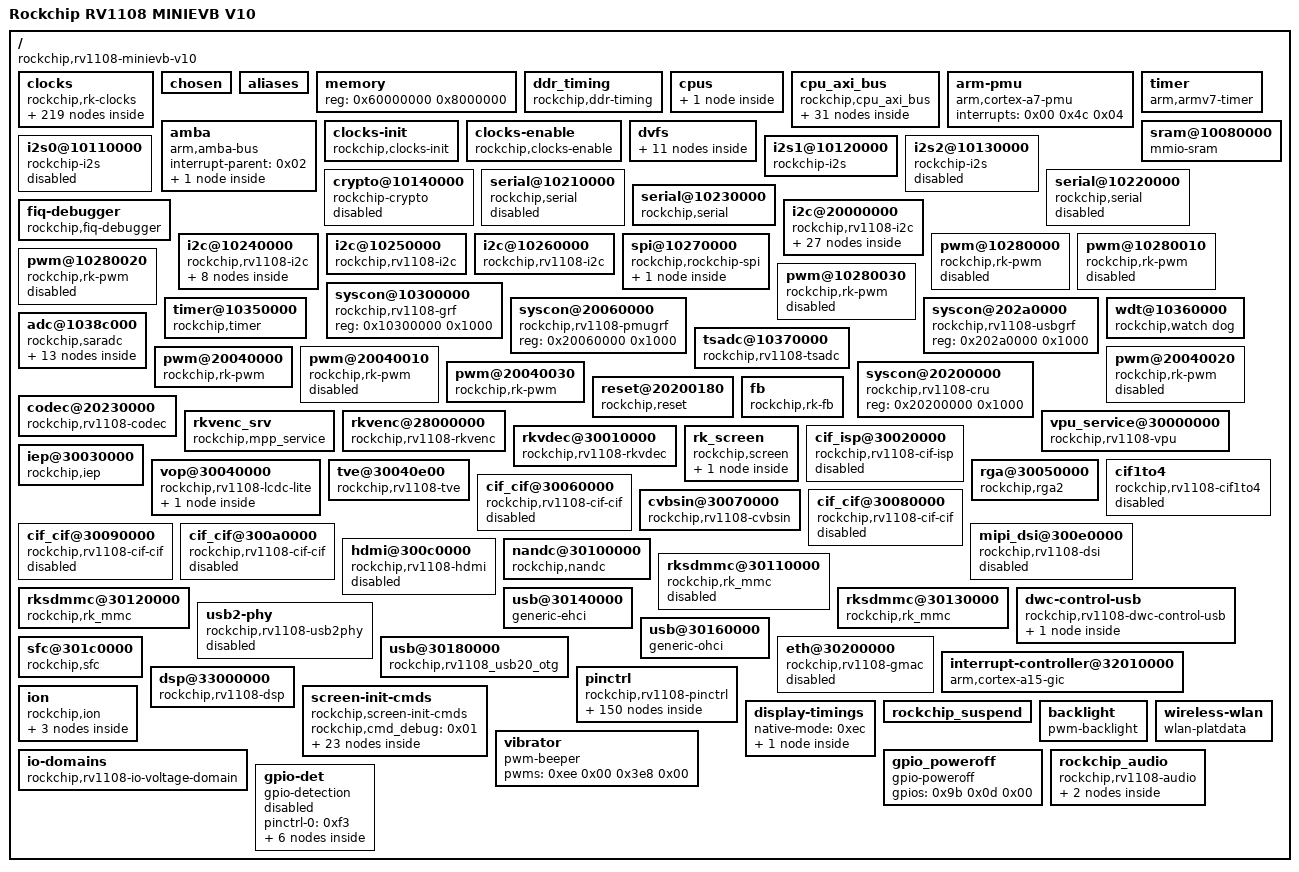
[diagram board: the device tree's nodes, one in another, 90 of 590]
/dts-v1/;

/ {
	#address-cells = <0x01>;
	#size-cells = <0x01>;
	compatible = "rockchip,rv1108-minievb-v10\0rockchip,rv1108";
	rockchip,sram = <0x01>;
	interrupt-parent = <0x02>;
	model = "Rockchip RV1108 MINIEVB V10";

	clocks {
		compatible = "rockchip,rk-clocks";
		#address-cells = <0x01>;
		#size-cells = <0x01>;
		ranges = <0x00 0x20200000 0x1000>;

		fixed_rate_cons {
			compatible = "rockchip,rk-fixed-rate-cons";

			xin24m {
				compatible = "rockchip,rk-fixed-clock";
				clock-output-names = "xin24m";
				clock-frequency = <0x16e3600>;
				#clock-cells = <0x00>;
				linux,phandle = <0x03>;
				phandle = <0x03>;
			};

			xin12m {
				compatible = "rockchip,rk-fixed-clock";
				clocks = <0x03>;
				clock-output-names = "xin12m";
				clock-frequency = <0xb71b00>;
				#clock-cells = <0x00>;
				linux,phandle = <0x12>;
				phandle = <0x12>;
			};

			hdmiphy_pll {
				compatible = "rockchip,rk-fixed-clock";
				clock-output-names = "hdmiphy_pll";
				clock-frequency = <0x2367b880>;
				#clock-cells = <0x00>;
				linux,phandle = <0x56>;
				phandle = <0x56>;
			};

			usbphy_480m {
				compatible = "rockchip,rk-fixed-clock";
				clock-output-names = "usbphy_480m";
				clock-frequency = <0x1c9c3800>;
				#clock-cells = <0x00>;
				linux,phandle = <0x57>;
				phandle = <0x57>;
			};

			pclkin_vip_ninv {
				compatible = "rockchip,rk-fixed-clock";
				clock-output-names = "pclkin_vip_ninv";
				clock-frequency = <0x8f0d180>;
				#clock-cells = <0x00>;
				linux,phandle = <0x3f>;
				phandle = <0x3f>;
			};

			pclkin_vip_inv {
				compatible = "rockchip,rk-fixed-clock";
				clock-output-names = "pclkin_vip_inv";
				clock-frequency = <0x8f0d180>;
				#clock-cells = <0x00>;
				linux,phandle = <0x40>;
				phandle = <0x40>;
			};

			i2s_clkin {
				compatible = "rockchip,rk-fixed-clock";
				clock-output-names = "i2s_clkin";
				clock-frequency = <0x00>;
				#clock-cells = <0x00>;
				linux,phandle = <0x11>;
				phandle = <0x11>;
			};

			gmac_clkin {
				compatible = "rockchip,rk-fixed-clock";
				clock-output-names = "gmac_clkin";
				clock-frequency = <0x2faf080>;
				#clock-cells = <0x00>;
				linux,phandle = <0x2f>;
				phandle = <0x2f>;
			};

			pclkin_cvbs2cif {
				compatible = "rockchip,rk-fixed-clock";
				clock-output-names = "pclkin_cvbs2cif";
				clock-frequency = <0x19bfcc0>;
				#clock-cells = <0x00>;
				linux,phandle = <0x3b>;
				phandle = <0x3b>;
			};

			pclk_cif0_out {
				compatible = "rockchip,rk-fixed-clock";
				clock-output-names = "pclk_cif0_out";
				clock-frequency = <0x8f0d180>;
				#clock-cells = <0x00>;
				linux,phandle = <0x3a>;
				phandle = <0x3a>;
			};

			pclk_cif1_out {
				compatible = "rockchip,rk-fixed-clock";
				clock-output-names = "pclk_cif1_out";
				clock-frequency = <0x8f0d180>;
				#clock-cells = <0x00>;
				linux,phandle = <0x3c>;
				phandle = <0x3c>;
			};

			pclk_cif2_out {
				compatible = "rockchip,rk-fixed-clock";
				clock-output-names = "pclk_cif2_out";
				clock-frequency = <0x8f0d180>;
				#clock-cells = <0x00>;
				linux,phandle = <0x3d>;
				phandle = <0x3d>;
			};

			pclk_cif3_out {
				compatible = "rockchip,rk-fixed-clock";
				clock-output-names = "pclk_cif3_out";
				clock-frequency = <0x8f0d180>;
				#clock-cells = <0x00>;
				linux,phandle = <0x3e>;
				phandle = <0x3e>;
			};

			io_cvbs_clkin {
				compatible = "rockchip,rk-fixed-clock";
				clock-output-names = "io_cvbs_clkin";
				clock-frequency = <0x337f980>;
				#clock-cells = <0x00>;
				linux,phandle = <0x47>;
				phandle = <0x47>;
			};

			clk_jtag_io {
				compatible = "rockchip,rk-fixed-clock";
				clock-output-names = "clk_jtag_io";
				clock-frequency = <0x00>;
				#clock-cells = <0x00>;
				linux,phandle = <0x58>;
				phandle = <0x58>;
			};

			dummy {
				compatible = "rockchip,rk-fixed-clock";
				clock-output-names = "dummy";
				clock-frequency = <0x00>;
				#clock-cells = <0x00>;
				linux,phandle = <0x0a>;
				phandle = <0x0a>;
			};
		};

		fixed_factor_cons {
			compatible = "rockchip,rk-fixed-factor-cons";

			hclk_rkvenc_pre {
				compatible = "rockchip,rk-fixed-factor-clock";
				clocks = <0x04>;
				clock-output-names = "hclk_rkvenc_pre";
				clock-div = <0x04>;
				clock-mult = <0x01>;
				#clock-cells = <0x00>;
				linux,phandle = <0x76>;
				phandle = <0x76>;
			};

			hclk_rkvdec_pre {
				compatible = "rockchip,rk-fixed-factor-clock";
				clocks = <0x05>;
				clock-output-names = "hclk_rkvdec_pre";
				clock-div = <0x04>;
				clock-mult = <0x01>;
				#clock-cells = <0x00>;
				linux,phandle = <0x75>;
				phandle = <0x75>;
			};
		};

		clock_regs {
			compatible = "rockchip,rk-clock-regs";
			#address-cells = <0x01>;
			#size-cells = <0x01>;
			reg = <0x00 0x1000>;
			ranges;

			pll_cons {
				compatible = "rockchip,rk-pll-cons";
				#address-cells = <0x01>;
				#size-cells = <0x01>;
				ranges;

				pll-clk@0000 {
					compatible = "rockchip,rk3188-pll-clk";
					reg = <0x00 0x18>;
					mode-reg = <0x0c 0x08>;
					status-reg = <0x08 0x1f>;
					clocks = <0x03>;
					clock-output-names = "clk_apll";
					rockchip,pll-type = <0x40>;
					#clock-cells = <0x00>;
					linux,phandle = <0x07>;
					phandle = <0x07>;
				};

				pll-clk@0020 {
					compatible = "rockchip,rk3188-pll-clk";
					reg = <0x20 0x18>;
					mode-reg = <0x2c 0x08>;
					status-reg = <0x28 0x1f>;
					clocks = <0x03>;
					clock-output-names = "clk_dpll";
					rockchip,pll-type = <0x100>;
					#clock-cells = <0x00>;
					linux,phandle = <0x09>;
					phandle = <0x09>;
				};

				pll-clk@0040 {
					compatible = "rockchip,rk3188-pll-clk";
					reg = <0x40 0x10>;
					mode-reg = <0x4c 0x08>;
					status-reg = <0x48 0x1f>;
					clocks = <0x03>;
					clock-output-names = "clk_gpll";
					rockchip,pll-type = <0x100>;
					#clock-cells = <0x00>;
					#clock-init-cells = <0x01>;
					linux,phandle = <0x08>;
					phandle = <0x08>;
				};
			};

			clk_sel_cons {
				compatible = "rockchip,rk-sel-cons";
				#address-cells = <0x01>;
				#size-cells = <0x01>;
				ranges;

				sel-con@0060 {
					compatible = "rockchip,rk3188-selcon";
					reg = <0x60 0x04>;
					#address-cells = <0x01>;
					#size-cells = <0x01>;

					clk_core_div {
						compatible = "rockchip,rk3188-div-con";
						rockchip,bits = <0x00 0x05>;
						clocks = <0x06>;
						clock-output-names = "clk_core";
						rockchip,div-type = <0x00>;
						#clock-cells = <0x00>;
						rockchip,clkops-idx = <0x0b>;
						rockchip,flags = <0xc0>;
					};

					clk_core_mux {
						compatible = "rockchip,rk3188-mux-con";
						rockchip,bits = <0x08 0x02>;
						clocks = <0x07 0x08 0x09 0x0a>;
						clock-output-names = "clk_core";
						#clock-cells = <0x00>;
						#clock-init-cells = <0x01>;
						linux,phandle = <0x06>;
						phandle = <0x06>;
					};
				};

				sel-con@0064 {
					compatible = "rockchip,rk3188-selcon";
					reg = <0x64 0x04>;
					#address-cells = <0x01>;
					#size-cells = <0x01>;

					aclk_core_div {
						compatible = "rockchip,rk3188-div-con";
						rockchip,bits = <0x00 0x03>;
						clocks = <0x06>;
						clock-output-names = "aclk_core";
						rockchip,div-type = <0x00>;
						#clock-cells = <0x00>;
						rockchip,clkops-idx = <0x0c>;
						linux,phandle = <0x6d>;
						phandle = <0x6d>;
					};

					pclk_dbg_div {
						compatible = "rockchip,rk3188-div-con";
						rockchip,bits = <0x04 0x04>;
						clocks = <0x06>;
						clock-output-names = "pclk_dbg";
						rockchip,div-type = <0x00>;
						#clock-cells = <0x00>;
						rockchip,clkops-idx = <0x0c>;
						linux,phandle = <0x6e>;
						phandle = <0x6e>;
					};
				};

				sel-con@0068 {
					compatible = "rockchip,rk3188-selcon";
					reg = <0x68 0x04>;
					#address-cells = <0x01>;
					#size-cells = <0x01>;

					aclk_bus_pre_div {
						compatible = "rockchip,rk3188-div-con";
						rockchip,bits = <0x00 0x05>;
						clocks = <0x0b>;
						clock-output-names = "aclk_bus_pre";
						rockchip,div-type = <0x00>;
						#clock-cells = <0x00>;
						#clock-init-cells = <0x01>;
						rockchip,clkops-idx = <0x01>;
						rockchip,flags = <0x100>;
						linux,phandle = <0x0c>;
						phandle = <0x0c>;
					};

					aclk_bus_pre_mux {
						compatible = "rockchip,rk3188-mux-con";
						rockchip,bits = <0x08 0x02>;
						clocks = <0x08 0x0a 0x0a 0x0a>;
						clock-output-names = "aclk_bus_pre";
						#clock-cells = <0x00>;
						#clock-init-cells = <0x01>;
						linux,phandle = <0x0b>;
						phandle = <0x0b>;
					};
				};

				sel-con@006c {
					compatible = "rockchip,rk3188-selcon";
					reg = <0x6c 0x04>;
					#address-cells = <0x01>;
					#size-cells = <0x01>;

					hclk_bus_pre_div {
						compatible = "rockchip,rk3188-div-con";
						rockchip,bits = <0x00 0x05>;
						clocks = <0x0c>;
						clock-output-names = "hclk_bus_pre";
						rockchip,div-type = <0x00>;
						#clock-cells = <0x00>;
						#clock-init-cells = <0x01>;
						linux,phandle = <0x59>;
						phandle = <0x59>;
					};

					pclk_bus_pre_div {
						compatible = "rockchip,rk3188-div-con";
						rockchip,bits = <0x08 0x05>;
						clocks = <0x0c>;
						clock-output-names = "pclk_bus_pre";
						rockchip,div-type = <0x00>;
						#clock-cells = <0x00>;
						#clock-init-cells = <0x01>;
						linux,phandle = <0x5a>;
						phandle = <0x5a>;
					};
				};

				sel-con@0070 {
					compatible = "rockchip,rk3188-selcon";
					reg = <0x70 0x04>;
					#address-cells = <0x01>;
					#size-cells = <0x01>;

					clk_ddr_div {
						compatible = "rockchip,rk3188-div-con";
						rockchip,bits = <0x00 0x03>;
						clocks = <0x0d>;
						clock-output-names = "clk_ddr";
						rockchip,div-type = <0x80>;
						rockchip,div-relations = <0x00 0x01 0x01 0x02 0x03 0x04>;
						#clock-cells = <0x00>;
						rockchip,flags = <0xc0>;
						rockchip,clkops-idx = <0x12>;
						linux,phandle = <0x54>;
						phandle = <0x54>;
					};

					clk_ddr_pll_mux {
						compatible = "rockchip,rk3188-mux-con";
						rockchip,bits = <0x08 0x02>;
						clocks = <0x09 0x0a 0x08 0x0a>;
						clock-output-names = "clk_ddr";
						#clock-cells = <0x00>;
						linux,phandle = <0x0d>;
						phandle = <0x0d>;
					};
				};

				sel-con@0074 {
					compatible = "rockchip,rk3188-selcon";
					reg = <0x74 0x04>;
					#address-cells = <0x01>;
					#size-cells = <0x01>;

					clk_i2s0_pll_div {
						compatible = "rockchip,rk3188-div-con";
						rockchip,bits = <0x00 0x07>;
						clocks = <0x0e>;
						clock-output-names = "clk_i2s0_pll";
						rockchip,div-type = <0x00>;
						#clock-cells = <0x00>;
						rockchip,clkops-idx = <0x01>;
						rockchip,flags = <0x80>;
						linux,phandle = <0x0f>;
						phandle = <0x0f>;
					};

					clk_i2s0_pll_mux {
						compatible = "rockchip,rk3188-mux-con";
						rockchip,bits = <0x08 0x01>;
						clocks = <0x0a 0x08>;
						clock-output-names = "clk_i2s0_pll";
						#clock-cells = <0x00>;
						#clock-init-cells = <0x01>;
						linux,phandle = <0x0e>;
						phandle = <0x0e>;
					};

					clk_i2s0_mux {
						compatible = "rockchip,rk3188-mux-con";
						rockchip,bits = <0x0c 0x02>;
						clocks = <0x0f 0x10 0x11 0x12>;
						clock-output-names = "clk_i2s0";
						#clock-cells = <0x00>;
						rockchip,clkops-idx = <0x0e>;
						rockchip,flags = <0x04>;
						linux,phandle = <0x13>;
						phandle = <0x13>;
					};

					i2s0_clkout_mux {
						compatible = "rockchip,rk3188-mux-con";
						rockchip,bits = <0x0f 0x01>;
						clocks = <0x13 0x12>;
						clock-output-names = "i2s0_clkout";
						#clock-cells = <0x00>;
						#clock-init-cells = <0x01>;
						linux,phandle = <0x5b>;
						phandle = <0x5b>;
					};
				};

				sel-con@0078 {
					compatible = "rockchip,rk3188-selcon";
					reg = <0x78 0x04>;
					#address-cells = <0x01>;
					#size-cells = <0x01>;

					clk_i2s1_pll_div {
						compatible = "rockchip,rk3188-div-con";
						rockchip,bits = <0x00 0x07>;
						clocks = <0x14>;
						clock-output-names = "clk_i2s1_pll";
						rockchip,div-type = <0x00>;
						#clock-cells = <0x00>;
						rockchip,clkops-idx = <0x01>;
						rockchip,flags = <0x80>;
						linux,phandle = <0x15>;
						phandle = <0x15>;
					};

					clk_i2s1_pll_mux {
						compatible = "rockchip,rk3188-mux-con";
						rockchip,bits = <0x08 0x01>;
						clocks = <0x0a 0x08>;
						clock-output-names = "clk_i2s1_pll";
						#clock-cells = <0x00>;
						#clock-init-cells = <0x01>;
						linux,phandle = <0x14>;
						phandle = <0x14>;
					};

					clk_i2s1_mux {
						compatible = "rockchip,rk3188-mux-con";
						rockchip,bits = <0x0c 0x02>;
						clocks = <0x15 0x16 0x0a 0x12>;
						clock-output-names = "clk_i2s1";
						#clock-cells = <0x00>;
						rockchip,clkops-idx = <0x0e>;
						rockchip,flags = <0x04>;
						linux,phandle = <0x5c>;
						phandle = <0x5c>;
					};
				};

				sel-con@007c {
					compatible = "rockchip,rk3188-selcon";
					reg = <0x7c 0x04>;
					#address-cells = <0x01>;
					#size-cells = <0x01>;

					clk_i2s2_pll_div {
						compatible = "rockchip,rk3188-div-con";
						rockchip,bits = <0x00 0x07>;
						clocks = <0x17>;
						clock-output-names = "clk_i2s2_pll";
						rockchip,div-type = <0x00>;
						#clock-cells = <0x00>;
						rockchip,clkops-idx = <0x01>;
						rockchip,flags = <0x80>;
						linux,phandle = <0x18>;
						phandle = <0x18>;
					};

					clk_i2s2_pll_mux {
						compatible = "rockchip,rk3188-mux-con";
						rockchip,bits = <0x08 0x01>;
						clocks = <0x0a 0x08>;
						clock-output-names = "clk_i2s2_pll";
						#clock-cells = <0x00>;
						#clock-init-cells = <0x01>;
						linux,phandle = <0x17>;
						phandle = <0x17>;
					};

					clk_i2s2_mux {
						compatible = "rockchip,rk3188-mux-con";
						rockchip,bits = <0x0c 0x02>;
						clocks = <0x18 0x19 0x0a 0x12>;
						clock-output-names = "clk_i2s2";
						#clock-cells = <0x00>;
						rockchip,clkops-idx = <0x0e>;
						rockchip,flags = <0x04>;
						linux,phandle = <0x5d>;
						phandle = <0x5d>;
					};
				};

				sel-con@0080 {
					compatible = "rockchip,rk3188-selcon";
					reg = <0x80 0x04>;
					#address-cells = <0x01>;
					#size-cells = <0x01>;

					i2s0_frac {
						compatible = "rockchip,rk3188-frac-con";
						clocks = <0x0f>;
						clock-output-names = "i2s0_frac";
						rockchip,bits = <0x00 0x20>;
						rockchip,clkops-idx = <0x05>;
						#clock-cells = <0x00>;
						linux,phandle = <0x10>;
						phandle = <0x10>;
					};
				};

				sel-con@0084 {
					compatible = "rockchip,rk3188-selcon";
					reg = <0x84 0x04>;
					#address-cells = <0x01>;
					#size-cells = <0x01>;

					i2s1_frac {
						compatible = "rockchip,rk3188-frac-con";
						clocks = <0x15>;
						clock-output-names = "i2s1_frac";
						rockchip,bits = <0x00 0x20>;
						rockchip,clkops-idx = <0x05>;
						#clock-cells = <0x00>;
						linux,phandle = <0x16>;
						phandle = <0x16>;
					};
				};

				sel-con@0088 {
					compatible = "rockchip,rk3188-selcon";
					reg = <0x88 0x04>;
					#address-cells = <0x01>;
					#size-cells = <0x01>;

					i2s2_frac {
						compatible = "rockchip,rk3188-frac-con";
						clocks = <0x18>;
						clock-output-names = "i2s2_frac";
						rockchip,bits = <0x00 0x20>;
						rockchip,clkops-idx = <0x05>;
						#clock-cells = <0x00>;
						linux,phandle = <0x19>;
						phandle = <0x19>;
					};
				};

				sel-con@008c {
					compatible = "rockchip,rk3188-selcon";
					reg = <0x8c 0x04>;
					#address-cells = <0x01>;
					#size-cells = <0x01>;

					clk_crypto_div {
						compatible = "rockchip,rk3188-div-con";
						rockchip,bits = <0x00 0x05>;
						clocks = <0x1a>;
						clock-output-names = "clk_crypto";
						rockchip,div-type = <0x00>;
						rockchip,clkops-idx = <0x01>;
						#clock-cells = <0x00>;
						#clock-init-cells = <0x01>;
					};

					clk_crypto_mux {
						compatible = "rockchip,rk3188-mux-con";
						rockchip,bits = <0x07 0x01>;
						clocks = <0x0a 0x08>;
						clock-output-names = "clk_crypto";
						#clock-cells = <0x00>;
						#clock-init-cells = <0x01>;
						linux,phandle = <0x1a>;
						phandle = <0x1a>;
					};

					clk_spi_div {
						compatible = "rockchip,rk3188-div-con";
						rockchip,bits = <0x08 0x07>;
						clocks = <0x1b>;
						clock-output-names = "clk_spi";
						rockchip,div-type = <0x00>;
						#clock-cells = <0x00>;
						rockchip,clkops-idx = <0x01>;
					};

					clk_spi_mux {
						compatible = "rockchip,rk3188-mux-con";
						rockchip,bits = <0x0f 0x01>;
						clocks = <0x0a 0x08>;
						clock-output-names = "clk_spi";
						#clock-cells = <0x00>;
						linux,phandle = <0x1b>;
						phandle = <0x1b>;
					};
				};

				sel-con@0090 {
					compatible = "rockchip,rk3188-selcon";
					reg = <0x90 0x04>;
					#address-cells = <0x01>;
					#size-cells = <0x01>;

					clk_pwm0_div {
						compatible = "rockchip,rk3188-div-con";
						rockchip,bits = <0x00 0x07>;
						clocks = <0x1c>;
						clock-output-names = "clk_pwm0";
						rockchip,div-type = <0x00>;
						#clock-cells = <0x00>;
						rockchip,clkops-idx = <0x01>;
					};

					clk_pwm0_mux {
						compatible = "rockchip,rk3188-mux-con";
						rockchip,bits = <0x07 0x01>;
						clocks = <0x0a 0x08>;
						clock-output-names = "clk_pwm0";
						#clock-cells = <0x00>;
						linux,phandle = <0x1c>;
						phandle = <0x1c>;
					};

					clk_pwm1_div {
						compatible = "rockchip,rk3188-div-con";
						rockchip,bits = <0x08 0x07>;
						clocks = <0x1d>;
						clock-output-names = "clk_pwm1";
						rockchip,div-type = <0x00>;
						#clock-cells = <0x00>;
						rockchip,clkops-idx = <0x01>;
					};

					clk_pwm1_mux {
						compatible = "rockchip,rk3188-mux-con";
						rockchip,bits = <0x0f 0x01>;
						clocks = <0x0a 0x08>;
						clock-output-names = "clk_pwm1";
						#clock-cells = <0x00>;
						linux,phandle = <0x1d>;
						phandle = <0x1d>;
					};
				};

				sel-con@0094 {
					compatible = "rockchip,rk3188-selcon";
					reg = <0x94 0x04>;
					#address-cells = <0x01>;
					#size-cells = <0x01>;

					clk_uart0_pll_div {
						compatible = "rockchip,rk3188-div-con";
						rockchip,bits = <0x00 0x07>;
						clocks = <0x1e>;
						clock-output-names = "clk_uart0_pll";
						rockchip,div-type = <0x00>;
						#clock-cells = <0x00>;
						rockchip,clkops-idx = <0x01>;
						rockchip,flags = <0x80>;
						linux,phandle = <0x1f>;
						phandle = <0x1f>;
					};

					clk_uart0_mux {
						compatible = "rockchip,rk3188-mux-con";
						rockchip,bits = <0x08 0x02>;
						clocks = <0x1f 0x20 0x03>;
						clock-output-names = "clk_uart0";
						#clock-cells = <0x00>;
						rockchip,clkops-idx = <0x0e>;
						rockchip,flags = <0x04>;
						linux,phandle = <0x96>;
						phandle = <0x96>;
					};

					clk_uart0_pll_mux {
						compatible = "rockchip,rk3188-mux-con";
						rockchip,bits = <0x0c 0x02>;
						clocks = <0x0a 0x08 0x21>;
						clock-output-names = "clk_uart0_pll";
						#clock-cells = <0x00>;
						#clock-init-cells = <0x01>;
						linux,phandle = <0x1e>;
						phandle = <0x1e>;
					};
				};

				sel-con@0098 {
					compatible = "rockchip,rk3188-selcon";
					reg = <0x98 0x04>;
					#address-cells = <0x01>;
					#size-cells = <0x01>;

					clk_uart1_pll_div {
						compatible = "rockchip,rk3188-div-con";
						rockchip,bits = <0x00 0x07>;
						clocks = <0x22>;
						clock-output-names = "clk_uart1_pll";
						rockchip,div-type = <0x00>;
						#clock-cells = <0x00>;
						rockchip,clkops-idx = <0x01>;
						rockchip,flags = <0x80>;
						linux,phandle = <0x23>;
						phandle = <0x23>;
					};

					clk_uart1_mux {
						compatible = "rockchip,rk3188-mux-con";
						rockchip,bits = <0x08 0x02>;
						clocks = <0x23 0x24 0x03>;
						clock-output-names = "clk_uart1";
						#clock-cells = <0x00>;
						rockchip,clkops-idx = <0x0e>;
						rockchip,flags = <0x04>;
						linux,phandle = <0x92>;
						phandle = <0x92>;
					};

					clk_uart1_pll_mux {
						compatible = "rockchip,rk3188-mux-con";
						rockchip,bits = <0x0c 0x02>;
						clocks = <0x0a 0x08 0x21>;
						clock-output-names = "clk_uart1_pll";
						#clock-cells = <0x00>;
						#clock-init-cells = <0x01>;
						linux,phandle = <0x22>;
						phandle = <0x22>;
					};
				};

				sel-con@009c {
					compatible = "rockchip,rk3188-selcon";
					reg = <0x9c 0x04>;
					#address-cells = <0x01>;
					#size-cells = <0x01>;

					clk_uart2_pll_div {
						compatible = "rockchip,rk3188-div-con";
						rockchip,bits = <0x00 0x07>;
						clocks = <0x25>;
						clock-output-names = "clk_uart2_pll";
						rockchip,div-type = <0x00>;
						#clock-cells = <0x00>;
						rockchip,clkops-idx = <0x01>;
						rockchip,flags = <0x80>;
						linux,phandle = <0x27>;
						phandle = <0x27>;
					};

					clk_uart2_mux {
						compatible = "rockchip,rk3188-mux-con";
						rockchip,bits = <0x08 0x02>;
						clocks = <0x25 0x26 0x03>;
						clock-output-names = "clk_uart2";
						#clock-cells = <0x00>;
						rockchip,clkops-idx = <0x0e>;
						rockchip,flags = <0x04>;
						linux,phandle = <0x90>;
						phandle = <0x90>;
					};

					clk_uart2_pll_mux {
						compatible = "rockchip,rk3188-mux-con";
						rockchip,bits = <0x0c 0x02>;
						clocks = <0x0a 0x08 0x21>;
						clock-output-names = "clk_uart2_pll";
						#clock-cells = <0x00>;
						#clock-init-cells = <0x01>;
						linux,phandle = <0x25>;
						phandle = <0x25>;
					};
				};

				sel-con@00a0 {
					compatible = "rockchip,rk3188-selcon";
					reg = <0xa0 0x04>;
					#address-cells = <0x01>;
					#size-cells = <0x01>;

					uart0_frac {
						compatible = "rockchip,rk3188-frac-con";
						clocks = <0x1f>;
						clock-output-names = "uart0_frac";
						rockchip,bits = <0x00 0x20>;
						rockchip,clkops-idx = <0x05>;
						#clock-cells = <0x00>;
						linux,phandle = <0x20>;
						phandle = <0x20>;
					};
				};

				sel-con@00a4 {
					compatible = "rockchip,rk3188-selcon";
					reg = <0xa4 0x04>;
					#address-cells = <0x01>;
					#size-cells = <0x01>;

					uart0_frac {
						compatible = "rockchip,rk3188-frac-con";
						clocks = <0x23>;
						clock-output-names = "uart1_frac";
						rockchip,bits = <0x00 0x20>;
						rockchip,clkops-idx = <0x05>;
						#clock-cells = <0x00>;
						linux,phandle = <0x24>;
						phandle = <0x24>;
					};
				};

				sel-con@00a8 {
					compatible = "rockchip,rk3188-selcon";
					reg = <0xa8 0x04>;
					#address-cells = <0x01>;
					#size-cells = <0x01>;

					uart1_frac {
						compatible = "rockchip,rk3188-frac-con";
						clocks = <0x27>;
						clock-output-names = "uart2_frac";
						rockchip,bits = <0x00 0x20>;
						rockchip,clkops-idx = <0x05>;
						#clock-cells = <0x00>;
						linux,phandle = <0x26>;
						phandle = <0x26>;
					};
				};

				sel-con@00ac {
					compatible = "rockchip,rk3188-selcon";
					reg = <0xac 0x04>;
					#address-cells = <0x01>;
					#size-cells = <0x01>;

					clk_i2c0_div {
						compatible = "rockchip,rk3188-div-con";
						rockchip,bits = <0x00 0x07>;
						clocks = <0x28>;
						clock-output-names = "clk_i2c0";
						rockchip,div-type = <0x00>;
						#clock-cells = <0x00>;
						rockchip,clkops-idx = <0x01>;
					};

					clk_i2c0_mux {
						compatible = "rockchip,rk3188-mux-con";
						rockchip,bits = <0x07 0x01>;
						clocks = <0x0a 0x08>;
						clock-output-names = "clk_i2c0";
						#clock-cells = <0x00>;
						linux,phandle = <0x28>;
						phandle = <0x28>;
					};

					clk_i2c1_div {
						compatible = "rockchip,rk3188-div-con";
						rockchip,bits = <0x08 0x07>;
						clocks = <0x29>;
						clock-output-names = "clk_i2c1";
						rockchip,div-type = <0x00>;
						#clock-cells = <0x00>;
						rockchip,clkops-idx = <0x01>;
					};

					clk_i2c1_mux {
						compatible = "rockchip,rk3188-mux-con";
						rockchip,bits = <0x0f 0x01>;
						clocks = <0x0a 0x08>;
						clock-output-names = "clk_i2c1";
						#clock-cells = <0x00>;
						linux,phandle = <0x29>;
						phandle = <0x29>;
					};
				};

				sel-con@00b0 {
					compatible = "rockchip,rk3188-selcon";
					reg = <0xb0 0x04>;
					#address-cells = <0x01>;
					#size-cells = <0x01>;

					clk_i2c2_div {
						compatible = "rockchip,rk3188-div-con";
						rockchip,bits = <0x00 0x07>;
						clocks = <0x2a>;
						clock-output-names = "clk_i2c2";
						rockchip,div-type = <0x00>;
						#clock-cells = <0x00>;
						rockchip,clkops-idx = <0x01>;
					};

					clk_i2c2_mux {
						compatible = "rockchip,rk3188-mux-con";
						rockchip,bits = <0x07 0x01>;
						clocks = <0x0a 0x08>;
						clock-output-names = "clk_i2c2";
						#clock-cells = <0x00>;
						linux,phandle = <0x2a>;
						phandle = <0x2a>;
					};

					clk_i2c3_div {
						compatible = "rockchip,rk3188-div-con";
						rockchip,bits = <0x08 0x07>;
						clocks = <0x2b>;
						clock-output-names = "clk_i2c3";
						rockchip,div-type = <0x00>;
						#clock-cells = <0x00>;
						rockchip,clkops-idx = <0x01>;
					};

					clk_i2c3_mux {
						compatible = "rockchip,rk3188-mux-con";
						rockchip,bits = <0x0f 0x01>;
						clocks = <0x0a 0x08>;
						clock-output-names = "clk_i2c3";
						#clock-cells = <0x00>;
						linux,phandle = <0x2b>;
						phandle = <0x2b>;
					};
				};

				sel-con@00b4 {
					compatible = "rockchip,rk3188-selcon";
					reg = <0xb4 0x04>;
					#address-cells = <0x01>;
					#size-cells = <0x01>;

					clk_tsadc_div {
						compatible = "rockchip,rk3188-div-con";
						rockchip,bits = <0x00 0x0a>;
						clocks = <0x03>;
						clock-output-names = "clk_tsadc";
						rockchip,div-type = <0x00>;
						#clock-cells = <0x00>;
						rockchip,clkops-idx = <0x01>;
						linux,phandle = <0x5e>;
						phandle = <0x5e>;
					};
				};

				sel-con@00b8 {
					compatible = "rockchip,rk3188-selcon";
					reg = <0xb8 0x04>;
					#address-cells = <0x01>;
					#size-cells = <0x01>;

					clk_saradc_div {
						compatible = "rockchip,rk3188-div-con";
						rockchip,bits = <0x00 0x0a>;
						clocks = <0x03>;
						clock-output-names = "clk_saradc";
						rockchip,div-type = <0x00>;
						#clock-cells = <0x00>;
						rockchip,clkops-idx = <0x01>;
						linux,phandle = <0x5f>;
						phandle = <0x5f>;
					};
				};

				sel-con@00bc {
					compatible = "rockchip,rk3188-selcon";
					reg = <0xbc 0x04>;
					#address-cells = <0x01>;
					#size-cells = <0x01>;

					aclk_peri_div {
						compatible = "rockchip,rk3188-div-con";
						rockchip,bits = <0x00 0x05>;
						clocks = <0x2c>;
						clock-output-names = "aclk_peri";
						rockchip,div-type = <0x00>;
						#clock-cells = <0x00>;
						rockchip,clkops-idx = <0x01>;
					};

					hclk_peri_div {
						compatible = "rockchip,rk3188-div-con";
						rockchip,bits = <0x05 0x05>;
						clocks = <0x08>;
						clock-output-names = "hclk_peri";
						rockchip,div-type = <0x00>;
						#clock-cells = <0x00>;
						rockchip,clkops-idx = <0x01>;
						#clock-init-cells = <0x01>;
						linux,phandle = <0x70>;
						phandle = <0x70>;
					};

					pclk_peri_div {
						compatible = "rockchip,rk3188-div-con";
						rockchip,bits = <0x0a 0x05>;
						clocks = <0x08>;
						clock-output-names = "pclk_peri";
						rockchip,div-type = <0x00>;
						#clock-cells = <0x00>;
						rockchip,clkops-idx = <0x01>;
						#clock-init-cells = <0x01>;
						linux,phandle = <0x71>;
						phandle = <0x71>;
					};

					aclk_peri_mux {
						compatible = "rockchip,rk3188-mux-con";
						rockchip,bits = <0x0f 0x01>;
						clocks = <0x08 0x0a>;
						clock-output-names = "aclk_peri";
						#clock-cells = <0x00>;
						#clock-init-cells = <0x01>;
						linux,phandle = <0x2c>;
						phandle = <0x2c>;
					};
				};

				sel-con@00c0 {
					compatible = "rockchip,rk3188-selcon";
					reg = <0xc0 0x04>;
					#address-cells = <0x01>;
					#size-cells = <0x01>;

					clk_mac_pll_div {
						compatible = "rockchip,rk3188-div-con";
						rockchip,bits = <0x00 0x05>;
						clocks = <0x2d>;
						clock-output-names = "clk_mac_pll";
						rockchip,div-type = <0x00>;
						#clock-cells = <0x00>;
						rockchip,clkops-idx = <0x01>;
						rockchip,flags = <0x100>;
						linux,phandle = <0x2e>;
						phandle = <0x2e>;
					};

					clk_mac_mux {
						compatible = "rockchip,rk3188-mux-con";
						rockchip,bits = <0x08 0x01>;
						clocks = <0x2e 0x2f>;
						clock-output-names = "clk_mac";
						#clock-cells = <0x00>;
						rockchip,flags = <0x04>;
						#clock-init-cells = <0x01>;
						linux,phandle = <0x60>;
						phandle = <0x60>;
					};

					clk_mac_pll_mux {
						compatible = "rockchip,rk3188-mux-con";
						rockchip,bits = <0x0c 0x01>;
						clocks = <0x07 0x08>;
						clock-output-names = "clk_mac_pll";
						#clock-cells = <0x00>;
						rockchip,flags = <0xc0>;
						#clock-init-cells = <0x01>;
						linux,phandle = <0x2d>;
						phandle = <0x2d>;
					};
				};

				sel-con@00c4 {
					compatible = "rockchip,rk3188-selcon";
					reg = <0xc4 0x04>;
					#address-cells = <0x01>;
					#size-cells = <0x01>;

					clk_sdmmc_div {
						compatible = "rockchip,rk3188-div-con";
						rockchip,bits = <0x00 0x08>;
						clocks = <0x30>;
						clock-output-names = "clk_sdmmc";
						rockchip,div-type = <0x00>;
						#clock-cells = <0x00>;
						rockchip,clkops-idx = <0x01>;
						rockchip,flags = <0x100>;
					};

					clk_sdmmc_mux {
						compatible = "rockchip,rk3188-mux-con";
						rockchip,bits = <0x08 0x02>;
						clocks = <0x0a 0x08 0x03 0x21>;
						clock-output-names = "clk_sdmmc";
						#clock-cells = <0x00>;
						linux,phandle = <0x30>;
						phandle = <0x30>;
					};

					clk_sdio_mux {
						compatible = "rockchip,rk3188-mux-con";
						rockchip,bits = <0x0a 0x02>;
						clocks = <0x0a 0x08 0x03 0x21>;
						clock-output-names = "clk_sdio";
						#clock-cells = <0x00>;
						#clock-init-cells = <0x01>;
						linux,phandle = <0x31>;
						phandle = <0x31>;
					};

					clk_emmc_mux {
						compatible = "rockchip,rk3188-mux-con";
						rockchip,bits = <0x0c 0x02>;
						clocks = <0x0a 0x08 0x03 0x21>;
						clock-output-names = "clk_emmc";
						#clock-cells = <0x00>;
						#clock-init-cells = <0x01>;
						linux,phandle = <0x32>;
						phandle = <0x32>;
					};
				};

				sel-con@00c8 {
					compatible = "rockchip,rk3188-selcon";
					reg = <0xc8 0x04>;
					#address-cells = <0x01>;
					#size-cells = <0x01>;

					clk_sdio_div {
						compatible = "rockchip,rk3188-div-con";
						rockchip,bits = <0x00 0x08>;
						clocks = <0x31>;
						clock-output-names = "clk_sdio";
						rockchip,div-type = <0x00>;
						#clock-cells = <0x00>;
						rockchip,clkops-idx = <0x01>;
						rockchip,flags = <0x100>;
					};

					clk_emmc_div {
						compatible = "rockchip,rk3188-div-con";
						rockchip,bits = <0x08 0x08>;
						clocks = <0x32>;
						clock-output-names = "clk_emmc";
						rockchip,div-type = <0x00>;
						#clock-cells = <0x00>;
						rockchip,clkops-idx = <0x01>;
						rockchip,flags = <0x100>;
					};
				};

				sel-con@00cc {
					compatible = "rockchip,rk3188-selcon";
					reg = <0xcc 0x04>;
					#address-cells = <0x01>;
					#size-cells = <0x01>;

					clk_sfc_div {
						compatible = "rockchip,rk3188-div-con";
						rockchip,bits = <0x00 0x07>;
						clocks = <0x33>;
						clock-output-names = "clk_sfc";
						rockchip,div-type = <0x00>;
						#clock-cells = <0x00>;
						rockchip,clkops-idx = <0x01>;
					};

					clk_sfc_mux {
						compatible = "rockchip,rk3188-mux-con";
						rockchip,bits = <0x07 0x01>;
						clocks = <0x0a 0x08>;
						clock-output-names = "clk_sfc";
						#clock-cells = <0x00>;
						linux,phandle = <0x33>;
						phandle = <0x33>;
					};

					clk_nandc_div {
						compatible = "rockchip,rk3188-div-con";
						rockchip,bits = <0x08 0x05>;
						clocks = <0x34>;
						clock-output-names = "clk_nandc";
						rockchip,div-type = <0x00>;
						#clock-cells = <0x00>;
						rockchip,clkops-idx = <0x01>;
					};

					clk_nandc_mux {
						compatible = "rockchip,rk3188-mux-con";
						rockchip,bits = <0x0e 0x01>;
						clocks = <0x0a 0x08>;
						clock-output-names = "clk_nandc";
						#clock-cells = <0x00>;
						#clock-init-cells = <0x01>;
						linux,phandle = <0x34>;
						phandle = <0x34>;
					};
				};

				sel-con@00d0 {
					compatible = "rockchip,rk3188-selcon";
					reg = <0xd0 0x04>;
					#address-cells = <0x01>;
					#size-cells = <0x01>;

					aclk_vio0_pre_div {
						compatible = "rockchip,rk3188-div-con";
						rockchip,bits = <0x00 0x05>;
						clocks = <0x35>;
						clock-output-names = "aclk_vio0_pre";
						rockchip,div-type = <0x00>;
						#clock-cells = <0x00>;
						rockchip,clkops-idx = <0x01>;
						rockchip,flags = <0x100>;
						#clock-init-cells = <0x01>;
						linux,phandle = <0x37>;
						phandle = <0x37>;
					};

					aclk_vio0_pre_mux {
						compatible = "rockchip,rk3188-mux-con";
						rockchip,bits = <0x06 0x02>;
						clocks = <0x0a 0x08 0x0a 0x21>;
						clock-output-names = "aclk_vio0_pre";
						#clock-cells = <0x00>;
						#clock-init-cells = <0x01>;
						linux,phandle = <0x35>;
						phandle = <0x35>;
					};

					aclk_vio1_pre_div {
						compatible = "rockchip,rk3188-div-con";
						rockchip,bits = <0x08 0x05>;
						clocks = <0x36>;
						clock-output-names = "aclk_vio1_pre";
						rockchip,div-type = <0x00>;
						#clock-cells = <0x00>;
						rockchip,clkops-idx = <0x01>;
						rockchip,flags = <0x100>;
						#clock-init-cells = <0x01>;
					};

					aclk_vio1_pre_mux {
						compatible = "rockchip,rk3188-mux-con";
						rockchip,bits = <0x0e 0x02>;
						clocks = <0x0a 0x08 0x0a 0x21>;
						clock-output-names = "aclk_vio1_pre";
						#clock-cells = <0x00>;
						#clock-init-cells = <0x01>;
						linux,phandle = <0x36>;
						phandle = <0x36>;
					};
				};

				sel-con@00d4 {
					compatible = "rockchip,rk3188-selcon";
					reg = <0xd4 0x04>;
					#address-cells = <0x01>;
					#size-cells = <0x01>;

					hclk_vio_pre_div {
						compatible = "rockchip,rk3188-div-con";
						rockchip,bits = <0x00 0x05>;
						clocks = <0x37>;
						clock-output-names = "hclk_vio_pre";
						rockchip,div-type = <0x00>;
						#clock-cells = <0x00>;
						rockchip,clkops-idx = <0x01>;
						#clock-init-cells = <0x01>;
						linux,phandle = <0x72>;
						phandle = <0x72>;
					};

					pclk_vio_pre_div {
						compatible = "rockchip,rk3188-div-con";
						rockchip,bits = <0x08 0x05>;
						clocks = <0x37>;
						clock-output-names = "pclk_vio_pre";
						rockchip,div-type = <0x00>;
						#clock-cells = <0x00>;
						rockchip,clkops-idx = <0x01>;
						#clock-init-cells = <0x01>;
						linux,phandle = <0x73>;
						phandle = <0x73>;
					};
				};

				sel-con@00d8 {
					compatible = "rockchip,rk3188-selcon";
					reg = <0xd8 0x04>;
					#address-cells = <0x01>;
					#size-cells = <0x01>;

					clk_isp_div {
						compatible = "rockchip,rk3188-div-con";
						rockchip,bits = <0x08 0x05>;
						clocks = <0x38>;
						clock-output-names = "clk_isp";
						rockchip,div-type = <0x00>;
						#clock-cells = <0x00>;
						rockchip,clkops-idx = <0x01>;
						rockchip,flags = <0x100>;
					};

					clk_isp_mux {
						compatible = "rockchip,rk3188-mux-con";
						rockchip,bits = <0x0e 0x02>;
						clocks = <0x0a 0x08 0x0a 0x21>;
						clock-output-names = "clk_isp";
						#clock-cells = <0x00>;
						#clock-init-cells = <0x01>;
						linux,phandle = <0x38>;
						phandle = <0x38>;
					};
				};

				sel-con@00dc {
					compatible = "rockchip,rk3188-selcon";
					reg = <0xdc 0x04>;
					#address-cells = <0x01>;
					#size-cells = <0x01>;

					vip0_clk_mux {
						compatible = "rockchip,rk3188-mux-con";
						rockchip,bits = <0x00 0x02>;
						clocks = <0x39 0x3a 0x3b 0x3b>;
						clock-output-names = "vip0_clk";
						#clock-cells = <0x00>;
						#clock-init-cells = <0x01>;
						linux,phandle = <0x61>;
						phandle = <0x61>;
					};

					vip1_clk_mux {
						compatible = "rockchip,rk3188-mux-con";
						rockchip,bits = <0x02 0x02>;
						clocks = <0x39 0x3c 0x3b 0x3b>;
						clock-output-names = "vip1_clk";
						#clock-cells = <0x00>;
						#clock-init-cells = <0x01>;
						linux,phandle = <0x62>;
						phandle = <0x62>;
					};

					vip2_clk_mux {
						compatible = "rockchip,rk3188-mux-con";
						rockchip,bits = <0x04 0x02>;
						clocks = <0x39 0x3d 0x3b 0x3b>;
						clock-output-names = "vip2_clk";
						#clock-cells = <0x00>;
						#clock-init-cells = <0x01>;
						linux,phandle = <0x63>;
						phandle = <0x63>;
					};

					vip3_clk_mux {
						compatible = "rockchip,rk3188-mux-con";
						rockchip,bits = <0x06 0x02>;
						clocks = <0x39 0x3e 0x3b 0x3b>;
						clock-output-names = "vip3_clk";
						#clock-cells = <0x00>;
						#clock-init-cells = <0x01>;
						linux,phandle = <0x64>;
						phandle = <0x64>;
					};

					pclkin_vip_mux {
						compatible = "rockchip,rk3188-mux-con";
						rockchip,bits = <0x08 0x01>;
						clocks = <0x3f 0x40>;
						clock-output-names = "pclkin_vip";
						#clock-cells = <0x00>;
						#clock-init-cells = <0x01>;
						linux,phandle = <0x39>;
						phandle = <0x39>;
					};
				};

				sel-con@00e0 {
					compatible = "rockchip,rk3188-selcon";
					reg = <0xe0 0x04>;
					#address-cells = <0x01>;
					#size-cells = <0x01>;

					dclk_vop_div {
						compatible = "rockchip,rk3188-div-con";
						rockchip,bits = <0x00 0x06>;
						clocks = <0x41>;
						clock-output-names = "dclk_vop";
						rockchip,div-type = <0x00>;
						#clock-cells = <0x00>;
						linux,phandle = <0x43>;
						phandle = <0x43>;
					};

					dclk_vop_pll_mux {
						compatible = "rockchip,rk3188-mux-con";
						rockchip,bits = <0x06 0x01>;
						clocks = <0x08 0x0a>;
						clock-output-names = "dclk_vop_pll";
						#clock-cells = <0x00>;
						#clock-init-cells = <0x01>;
						linux,phandle = <0x41>;
						phandle = <0x41>;
					};

					dclk_lcdc_mux {
						compatible = "rockchip,rk3188-mux-con";
						rockchip,bits = <0x07 0x01>;
						clocks = <0x42 0x43>;
						clock-output-names = "dclk_lcdc";
						rockchip,flags = <0x04>;
						#clock-cells = <0x00>;
						#clock-init-cells = <0x01>;
						linux,phandle = <0x55>;
						phandle = <0x55>;
					};

					dclk_hdmiphy_div {
						compatible = "rockchip,rk3188-div-con";
						rockchip,bits = <0x08 0x06>;
						clocks = <0x41>;
						clock-output-names = "dclk_hdmiphy";
						rockchip,div-type = <0x00>;
						#clock-cells = <0x00>;
						linux,phandle = <0xcf>;
						phandle = <0xcf>;
					};

					dclk_lcdc_pll_mux {
						compatible = "rockchip,rk3188-mux-con";
						rockchip,bits = <0x0f 0x01>;
						clocks = <0x44 0x03>;
						clock-output-names = "dclk_lcdc_pll";
						#clock-cells = <0x00>;
						#clock-init-cells = <0x01>;
						linux,phandle = <0x42>;
						phandle = <0x42>;
					};
				};

				sel-con@00e4 {
					compatible = "rockchip,rk3188-selcon";
					reg = <0xe4 0x04>;
					#address-cells = <0x01>;
					#size-cells = <0x01>;

					clk_rga_div {
						compatible = "rockchip,rk3188-div-con";
						rockchip,bits = <0x00 0x05>;
						clocks = <0x45>;
						clock-output-names = "clk_rga";
						rockchip,div-type = <0x00>;
						#clock-cells = <0x00>;
						rockchip,clkops-idx = <0x01>;
						rockchip,flags = <0x100>;
						#clock-init-cells = <0x01>;
					};

					clk_rga_mux {
						compatible = "rockchip,rk3188-mux-con";
						rockchip,bits = <0x06 0x02>;
						clocks = <0x0a 0x08 0x0a 0x21>;
						clock-output-names = "clk_rga";
						#clock-cells = <0x00>;
						#clock-init-cells = <0x01>;
						linux,phandle = <0x45>;
						phandle = <0x45>;
					};

					clk_cvbs_host_div {
						compatible = "rockchip,rk3188-div-con";
						rockchip,bits = <0x08 0x05>;
						clocks = <0x46>;
						clock-output-names = "clk_cvbs_host";
						rockchip,div-type = <0x00>;
						#clock-cells = <0x00>;
						rockchip,clkops-idx = <0x01>;
						rockchip,flags = <0x180>;
					};

					clk_cvbs_host_mux {
						compatible = "rockchip,rk3188-mux-con";
						rockchip,bits = <0x0d 0x02>;
						clocks = <0x0a 0x47 0x0a 0x08>;
						clock-output-names = "clk_cvbs_host";
						#clock-cells = <0x00>;
						#clock-init-cells = <0x01>;
						linux,phandle = <0x46>;
						phandle = <0x46>;
					};
				};

				sel-con@00e8 {
					compatible = "rockchip,rk3188-selcon";
					reg = <0xe8 0x04>;
					#address-cells = <0x01>;
					#size-cells = <0x01>;

					clk_hdmi_cec_div {
						compatible = "rockchip,rk3188-div-con";
						rockchip,bits = <0x00 0x0e>;
						clocks = <0x48>;
						clock-output-names = "clk_hdmi_cec";
						rockchip,div-type = <0x00>;
						#clock-cells = <0x00>;
						rockchip,clkops-idx = <0x01>;
					};

					clk_hdmi_cec_mux {
						compatible = "rockchip,rk3188-mux-con";
						rockchip,bits = <0x0e 0x02>;
						clocks = <0x0a 0x08 0x03 0x0a>;
						clock-output-names = "clk_hdmi_cec";
						#clock-cells = <0x00>;
						#clock-init-cells = <0x01>;
						linux,phandle = <0x48>;
						phandle = <0x48>;
					};
				};

				sel-con@00ec {
					compatible = "rockchip,rk3188-selcon";
					reg = <0xec 0x04>;
					#address-cells = <0x01>;
					#size-cells = <0x01>;

					aclk_rkvdec_pre_div {
						compatible = "rockchip,rk3188-div-con";
						rockchip,bits = <0x00 0x05>;
						clocks = <0x49>;
						clock-output-names = "aclk_rkvdec_pre";
						rockchip,div-type = <0x00>;
						#clock-cells = <0x00>;
						rockchip,clkops-idx = <0x01>;
						rockchip,flags = <0x100>;
					};

					aclk_rkvdec_pre_mux {
						compatible = "rockchip,rk3188-mux-con";
						rockchip,bits = <0x06 0x02>;
						clocks = <0x0a 0x08 0x0a 0x21>;
						clock-output-names = "aclk_rkvdec_pre";
						#clock-cells = <0x00>;
						#clock-init-cells = <0x01>;
						linux,phandle = <0x49>;
						phandle = <0x49>;
					};

					clk_hevc_cabac_div {
						compatible = "rockchip,rk3188-div-con";
						rockchip,bits = <0x08 0x05>;
						clocks = <0x4a>;
						clock-output-names = "clk_hevc_cabac";
						rockchip,div-type = <0x00>;
						#clock-cells = <0x00>;
						rockchip,clkops-idx = <0x01>;
						rockchip,flags = <0x100>;
					};

					clk_hevc_cabac_mux {
						compatible = "rockchip,rk3188-mux-con";
						rockchip,bits = <0x0e 0x02>;
						clocks = <0x0a 0x08 0x0a 0x21>;
						clock-output-names = "clk_hevc_cabac";
						#clock-cells = <0x00>;
						#clock-init-cells = <0x01>;
						linux,phandle = <0x4a>;
						phandle = <0x4a>;
					};
				};

				sel-con@00f0 {
					compatible = "rockchip,rk3188-selcon";
					reg = <0xf0 0x04>;
					#address-cells = <0x01>;
					#size-cells = <0x01>;

					clk_hevc_core_div {
						compatible = "rockchip,rk3188-div-con";
						rockchip,bits = <0x00 0x05>;
						clocks = <0x05>;
						clock-output-names = "clk_hevc_core";
						rockchip,div-type = <0x00>;
						#clock-cells = <0x00>;
						rockchip,clkops-idx = <0x01>;
						rockchip,flags = <0x100>;
						#clock-init-cells = <0x01>;
					};

					clk_hevc_core_mux {
						compatible = "rockchip,rk3188-mux-con";
						rockchip,bits = <0x06 0x02>;
						clocks = <0x0a 0x08 0x0a 0x21>;
						clock-output-names = "clk_hevc_core";
						#clock-cells = <0x00>;
						#clock-init-cells = <0x01>;
						linux,phandle = <0x05>;
						phandle = <0x05>;
					};

					aclk_vpu_pre_div {
						compatible = "rockchip,rk3188-div-con";
						rockchip,bits = <0x08 0x05>;
						clocks = <0x4b>;
						clock-output-names = "aclk_vpu_pre";
						rockchip,div-type = <0x00>;
						#clock-cells = <0x00>;
						rockchip,clkops-idx = <0x01>;
						rockchip,flags = <0x100>;
						#clock-init-cells = <0x01>;
					};

					aclk_vpu_pre_mux {
						compatible = "rockchip,rk3188-mux-con";
						rockchip,bits = <0x0e 0x02>;
						clocks = <0x0a 0x08 0x0a 0x21>;
						clock-output-names = "aclk_vpu_pre";
						#clock-cells = <0x00>;
						#clock-init-cells = <0x01>;
						linux,phandle = <0x4b>;
						phandle = <0x4b>;
					};
				};

				sel-con@00f4 {
					compatible = "rockchip,rk3188-selcon";
					reg = <0xf4 0x04>;
					#address-cells = <0x01>;
					#size-cells = <0x01>;

					aclk_rkvenc_pre_div {
						compatible = "rockchip,rk3188-div-con";
						rockchip,bits = <0x00 0x05>;
						clocks = <0x04>;
						clock-output-names = "aclk_rkvenc_pre";
						rockchip,div-type = <0x00>;
						#clock-cells = <0x00>;
						rockchip,clkops-idx = <0x01>;
						rockchip,flags = <0x100>;
					};

					aclk_rkvenc_pre_mux {
						compatible = "rockchip,rk3188-mux-con";
						rockchip,bits = <0x06 0x02>;
						clocks = <0x0a 0x08 0x0a 0x21>;
						clock-output-names = "aclk_rkvenc_pre";
						#clock-cells = <0x00>;
						#clock-init-cells = <0x01>;
						linux,phandle = <0x04>;
						phandle = <0x04>;
					};

					clk_venc_core_div {
						compatible = "rockchip,rk3188-div-con";
						rockchip,bits = <0x08 0x05>;
						clocks = <0x4c>;
						clock-output-names = "clk_venc_core";
						rockchip,div-type = <0x00>;
						#clock-cells = <0x00>;
						rockchip,clkops-idx = <0x01>;
						rockchip,flags = <0x100>;
					};

					clk_venc_core_mux {
						compatible = "rockchip,rk3188-mux-con";
						rockchip,bits = <0x0e 0x02>;
						clocks = <0x0a 0x08 0x0a 0x21>;
						clock-output-names = "clk_venc_core";
						#clock-cells = <0x00>;
						#clock-init-cells = <0x01>;
						linux,phandle = <0x4c>;
						phandle = <0x4c>;
					};
				};

				sel-con@00f8 {
					compatible = "rockchip,rk3188-selcon";
					reg = <0xf8 0x04>;
					#address-cells = <0x01>;
					#size-cells = <0x01>;

					pclk_pmu_pre_div {
						compatible = "rockchip,rk3188-div-con";
						rockchip,bits = <0x00 0x05>;
						clocks = <0x08>;
						clock-output-names = "pclk_pmu_pre";
						rockchip,div-type = <0x00>;
						#clock-cells = <0x00>;
						linux,phandle = <0x65>;
						phandle = <0x65>;
					};
				};

				sel-con@00fc {
					compatible = "rockchip,rk3188-selcon";
					reg = <0xfc 0x04>;
					#address-cells = <0x01>;
					#size-cells = <0x01>;

					clk_test_div {
						compatible = "rockchip,rk3188-div-con";
						rockchip,bits = <0x08 0x05>;
						clocks = <0x4d>;
						clock-output-names = "clk_test";
						rockchip,div-type = <0x00>;
						#clock-cells = <0x00>;
						rockchip,clkops-idx = <0x01>;
						linux,phandle = <0x6b>;
						phandle = <0x6b>;
					};
				};

				sel-con@0100 {
					compatible = "rockchip,rk3188-selcon";
					reg = <0x100 0x04>;
					#address-cells = <0x01>;
					#size-cells = <0x01>;

					clk_cif_out_div {
						compatible = "rockchip,rk3188-div-con";
						rockchip,bits = <0x00 0x05>;
						clocks = <0x4e>;
						clock-output-names = "clk_cif_out";
						rockchip,div-type = <0x00>;
						#clock-cells = <0x00>;
						rockchip,clkops-idx = <0x01>;
					};

					clk_cif_pll_mux {
						compatible = "rockchip,rk3188-mux-con";
						rockchip,bits = <0x08 0x01>;
						clocks = <0x0a 0x08>;
						clock-output-names = "clk_cif_pll";
						#clock-cells = <0x00>;
						linux,phandle = <0x4f>;
						phandle = <0x4f>;
					};

					clk_cif_out_mux {
						compatible = "rockchip,rk3188-mux-con";
						rockchip,bits = <0x0c 0x01>;
						clocks = <0x4f 0x03>;
						clock-output-names = "clk_cif_out";
						#clock-cells = <0x00>;
						linux,phandle = <0x4e>;
						phandle = <0x4e>;
					};
				};

				sel-con@0104 {
					compatible = "rockchip,rk3188-selcon";
					reg = <0x104 0x04>;
					#address-cells = <0x01>;
					#size-cells = <0x01>;

					clk_mipicsi_out_div {
						compatible = "rockchip,rk3188-div-con";
						rockchip,bits = <0x00 0x05>;
						clocks = <0x03>;
						clock-output-names = "clk_mipicsi_out";
						rockchip,div-type = <0x00>;
						#clock-cells = <0x00>;
						rockchip,clkops-idx = <0x01>;
						linux,phandle = <0x6c>;
						phandle = <0x6c>;
					};

					clk_wifi_div {
						compatible = "rockchip,rk3188-div-con";
						rockchip,bits = <0x08 0x06>;
						clocks = <0x50>;
						clock-output-names = "clk_wifi";
						rockchip,div-type = <0x00>;
						#clock-cells = <0x00>;
						rockchip,clkops-idx = <0x01>;
					};

					clk_wifi_mux {
						compatible = "rockchip,rk3188-mux-con";
						rockchip,bits = <0x0f 0x01>;
						clocks = <0x08 0x03>;
						clock-output-names = "clk_wifi";
						#clock-cells = <0x00>;
						linux,phandle = <0x50>;
						phandle = <0x50>;
					};
				};

				sel-con@0108 {
					compatible = "rockchip,rk3188-selcon";
					reg = <0x108 0x04>;
					#address-cells = <0x01>;
					#size-cells = <0x01>;

					clk_dsp_div {
						compatible = "rockchip,rk3188-div-con";
						rockchip,bits = <0x00 0x05>;
						clocks = <0x51>;
						clock-output-names = "clk_dsp";
						rockchip,div-type = <0x00>;
						#clock-cells = <0x00>;
						rockchip,clkops-idx = <0x01>;
						rockchip,flags = <0x100>;
						linux,phandle = <0x52>;
						phandle = <0x52>;
					};

					clk_dsp_mux {
						compatible = "rockchip,rk3188-mux-con";
						rockchip,bits = <0x08 0x02>;
						clocks = <0x0a 0x08 0x0a 0x21>;
						clock-output-names = "clk_dsp";
						#clock-cells = <0x00>;
						#clock-init-cells = <0x01>;
						linux,phandle = <0x51>;
						phandle = <0x51>;
					};
				};

				sel-con@010c {
					compatible = "rockchip,rk3188-selcon";
					reg = <0x10c 0x04>;
					#address-cells = <0x01>;
					#size-cells = <0x01>;

					clk_dsp_pfm_div {
						compatible = "rockchip,rk3188-div-con";
						rockchip,bits = <0x00 0x05>;
						clocks = <0x52>;
						clock-output-names = "clk_dsp_pfm";
						rockchip,div-type = <0x00>;
						#clock-cells = <0x00>;
						rockchip,clkops-idx = <0x01>;
						linux,phandle = <0x53>;
						phandle = <0x53>;
					};

					pclk_dsp_cfg_div {
						compatible = "rockchip,rk3188-div-con";
						rockchip,bits = <0x08 0x05>;
						clocks = <0x52>;
						clock-output-names = "pclk_dsp_cfg";
						rockchip,div-type = <0x00>;
						#clock-cells = <0x00>;
						rockchip,clkops-idx = <0x01>;
						linux,phandle = <0x6a>;
						phandle = <0x6a>;
					};
				};

				sel-con@0110 {
					compatible = "rockchip,rk3188-selcon";
					reg = <0x110 0x04>;
					#address-cells = <0x01>;
					#size-cells = <0x01>;

					clk_dsp_iop_div {
						compatible = "rockchip,rk3188-div-con";
						rockchip,bits = <0x00 0x05>;
						clocks = <0x52>;
						clock-output-names = "clk_dsp_iop";
						rockchip,div-type = <0x00>;
						#clock-cells = <0x00>;
						rockchip,clkops-idx = <0x01>;
						linux,phandle = <0x66>;
						phandle = <0x66>;
					};

					clk_dsp_epp_div {
						compatible = "rockchip,rk3188-div-con";
						rockchip,bits = <0x08 0x05>;
						clocks = <0x52>;
						clock-output-names = "clk_dsp_epp";
						rockchip,div-type = <0x00>;
						#clock-cells = <0x00>;
						rockchip,clkops-idx = <0x01>;
						linux,phandle = <0x67>;
						phandle = <0x67>;
					};
				};

				sel-con@0114 {
					compatible = "rockchip,rk3188-selcon";
					reg = <0x114 0x04>;
					#address-cells = <0x01>;
					#size-cells = <0x01>;

					clk_dsp_edp_div {
						compatible = "rockchip,rk3188-div-con";
						rockchip,bits = <0x00 0x05>;
						clocks = <0x52>;
						clock-output-names = "clk_dsp_edp";
						rockchip,div-type = <0x00>;
						#clock-cells = <0x00>;
						rockchip,clkops-idx = <0x01>;
						linux,phandle = <0x68>;
						phandle = <0x68>;
					};

					clk_dsp_edap_div {
						compatible = "rockchip,rk3188-div-con";
						rockchip,bits = <0x08 0x05>;
						clocks = <0x52>;
						clock-output-names = "clk_dsp_edap";
						rockchip,div-type = <0x00>;
						#clock-cells = <0x00>;
						rockchip,clkops-idx = <0x01>;
						linux,phandle = <0x69>;
						phandle = <0x69>;
					};
				};

				sel-con@01cc {
					compatible = "rockchip,rk3188-selcon";
					reg = <0x1cc 0x04>;
					#address-cells = <0x01>;
					#size-cells = <0x01>;

					clk_test_mux {
						compatible = "rockchip,rk3188-mux-con";
						rockchip,bits = <0x08 0x04>;
						clocks = <0x06 0x0c 0x35 0x36 0x2c 0x53 0x49 0x04 0x03 0x54 0x55 0x50 0x45 0x38 0x4b 0x4c>;
						clock-output-names = "clk_test_mux";
						#clock-cells = <0x00>;
						linux,phandle = <0x4d>;
						phandle = <0x4d>;
					};

					hdmiphy_mux {
						compatible = "rockchip,rk3188-mux-con";
						rockchip,bits = <0x0d 0x01>;
						clocks = <0x56 0x03>;
						clock-output-names = "hdmiphy";
						#clock-cells = <0x00>;
						#clock-init-cells = <0x01>;
						linux,phandle = <0x44>;
						phandle = <0x44>;
					};

					usb480m_mux {
						compatible = "rockchip,rk3188-mux-con";
						rockchip,bits = <0x0f 0x01>;
						clocks = <0x57 0x03>;
						clock-output-names = "usb480m";
						#clock-cells = <0x00>;
						#clock-init-cells = <0x01>;
						linux,phandle = <0x21>;
						phandle = <0x21>;
					};
				};
			};

			clk_gate_cons {
				compatible = "rockchip,rk-gate-cons";
				#address-cells = <0x01>;
				#size-cells = <0x01>;
				ranges;

				gate-clk@0120 {
					compatible = "rockchip,rk3188-gate-clk";
					reg = <0x120 0x04>;
					clocks = <0x07 0x0a 0x0a 0x58 0x06 0x06 0x0a 0x0a 0x0a 0x09 0x0a 0x03 0x0a 0x0a 0x0a 0x0a>;
					clock-output-names = "clk_core\0reserved\0reserved\0clk_jtag\0aclk_core\0pclk_dbg\0reserved\0reserved\0reserved\0clk_ddr\0reserved\0clk_ddrmon\0reserved\0reserved\0reserved\0reserved";
					rockchip,suspend-clkgating-setting = <0xf3f 0xf3f>;
					#clock-cells = <0x01>;
					linux,phandle = <0x7f>;
					phandle = <0x7f>;
				};

				gate-clk@0124 {
					compatible = "rockchip,rk3188-gate-clk";
					reg = <0x124 0x04>;
					clocks = <0x0c 0x0a 0x0a 0x0a 0x59 0x5a 0x5a 0x5a 0x5a 0x03 0x03 0x0a 0x0a 0x0a 0x0a 0x0a>;
					clock-output-names = "aclk_bus_pre\0reserved\0reserved\0reserved\0hclk_bus_pre\0pclk_bus_pre\0pclk_bus\0pclk_top\0pclk_ddr\0clk_timer0\0clk_timer1\0reserved\0reserved\0reserved\0reserved\0reserved";
					rockchip,suspend-clkgating-setting = <0x7f7 0x7f7>;
					#clock-cells = <0x01>;
					linux,phandle = <0x6f>;
					phandle = <0x6f>;
				};

				gate-clk@0128 {
					compatible = "rockchip,rk3188-gate-clk";
					reg = <0x128 0x04>;
					clocks = <0x0e 0x10 0x13 0x5b 0x14 0x16 0x5c 0x0a 0x17 0x19 0x5d 0x0a 0x1a 0x0a 0x0a 0x0a>;
					clock-output-names = "clk_i2s0_pll\0i2s0_frac\0clk_i2s0\0i2s0_clkout\0clk_i2s1_pll\0i2s1_frac\0clk_i2s1\0reserved\0clk_i2s2_pll\0i2s2_frac\0clk_i2s2\0reserved\0clk_crypto\0reserved\0reserved\0reserved";
					rockchip,suspend-clkgating-setting = <0x00 0x00>;
					#clock-cells = <0x01>;
				};

				gate-clk@012c {
					compatible = "rockchip,rk3188-gate-clk";
					reg = <0x12c 0x04>;
					clocks = <0x1b 0x1e 0x20 0x22 0x24 0x25 0x26 0x29 0x2a 0x2b 0x1d 0x5e 0x5f 0x0a 0x0a 0x0a>;
					clock-output-names = "clk_spi\0clk_uart0_pll\0uart0_frac\0clk_uart1_pll\0uart1_frac\0clk_uart2_pll\0uart2_frac\0clk_i2c1\0clk_i2c2\0clk_i2c3\0clk_pwm1\0clk_tsadc\0clk_saradc\0reserved\0reserved\0reserved";
					rockchip,suspend-clkgating-setting = <0x00 0x00>;
					#clock-cells = <0x01>;
					linux,phandle = <0xb5>;
					phandle = <0xb5>;
				};

				gate-clk@0130 {
					compatible = "rockchip,rk3188-gate-clk";
					reg = <0x130 0x04>;
					clocks = <0x0a 0x0a 0x2c 0x0a 0x08 0x08 0x60 0x60 0x60 0x60 0x2d 0x0a 0x0a 0x0a 0x0a 0x0a>;
					clock-output-names = "reserved\0reserved\0aclk_peri\0reserved\0hclk_peri\0pclk_peri\0clk_mac_ref\0clk_mac_refout\0clk_mac_rx\0reserved\0clk_mac_pll\0reserved\0reserved\0reserved\0reserved\0reserved";
					rockchip,suspend-clkgating-setting = <0x00 0x00>;
					#clock-cells = <0x01>;
					linux,phandle = <0xdf>;
					phandle = <0xdf>;
				};

				gate-clk@0134 {
					compatible = "rockchip,rk3188-gate-clk";
					reg = <0x134 0x04>;
					clocks = <0x30 0x32 0x31 0x34 0x33 0x03 0x0a 0x0a 0x0a 0x0a 0x0a 0x0a 0x0a 0x0a 0x0a 0x0a>;
					clock-output-names = "clk_sdmmc\0clk_emmc\0clk_sdio\0clk_nandc\0clk_sfc\0clk_usbphy\0reserved\0reserved\0reserved\0reserved\0reserved\0reserved\0reserved\0reserved\0reserved\0reserved";
					rockchip,suspend-clkgating-setting = <0x00 0x00>;
					#clock-cells = <0x01>;
					linux,phandle = <0xd3>;
					phandle = <0xd3>;
				};

				gate-clk@0138 {
					compatible = "rockchip,rk3188-gate-clk";
					reg = <0x138 0x04>;
					clocks = <0x0a 0x0a 0x0a 0x38 0x0a 0x43 0x45 0x46 0x03 0x48 0x0a 0x0a 0x0a 0x0a 0x0a 0x0a>;
					clock-output-names = "reserved\0reserved\0reserved\0clk_isp\0reserved\0dclk_vop\0clk_rga\0clk_cvbs_host\0clk_hdmi_sfr\0clk_hdmi_cec\0reserved\0reserved\0reserved\0reserved\0reserved\0reserved";
					rockchip,suspend-clkgating-setting = <0x00 0x00>;
					#clock-cells = <0x01>;
					linux,phandle = <0xcd>;
					phandle = <0xcd>;
				};

				gate-clk@013c {
					compatible = "rockchip,rk3188-gate-clk";
					reg = <0x13c 0x04>;
					clocks = <0x0a 0x0a 0x0a 0x0a 0x0a 0x0a 0x39 0x0a 0x39 0x61 0x62 0x63 0x64 0x0a 0x0a 0x0a>;
					clock-output-names = "reserved\0reserved\0reserved\0reserved\0reserved\0reserved\0pclk_isp_pre\0reserved\0pclk_cif1to4\0pclkin_cif0\0pclkin_cif1\0pclkin_cif2\0pclkin_cif3\0reserved\0reserved\0reserved";
					rockchip,suspend-clkgating-setting = <0x00 0x00>;
					#clock-cells = <0x01>;
					linux,phandle = <0x74>;
					phandle = <0x74>;
				};

				gate-clk@0140 {
					compatible = "rockchip,rk3188-gate-clk";
					reg = <0x140 0x04>;
					clocks = <0x0a 0x4a 0x05 0x0a 0x0a 0x0a 0x0a 0x0a 0x0a 0x4c 0x0a 0x0a 0x65 0x03 0x28 0x1c>;
					clock-output-names = "reserved\0clk_hevc_cabac\0clk_hevc_core\0reserved\0reserved\0reserved\0reserved\0reserved\0reserved\0clk_venc_core\0reserved\0reserved\0pclk_pmu_pre\0clk_pvtm_pmu\0clk_i2c0\0clk_pwm0";
					rockchip,suspend-clkgating-setting = <0x3000 0x3000>;
					#clock-cells = <0x01>;
					linux,phandle = <0xbd>;
					phandle = <0xbd>;
				};

				gate-clk@0144 {
					compatible = "rockchip,rk3188-gate-clk";
					reg = <0x144 0x04>;
					clocks = <0x51 0x66 0x67 0x68 0x69 0x6a 0x53 0x0a 0x50 0x6b 0x03 0x4e 0x6c 0x0a 0x0a 0x0a>;
					clock-output-names = "clk_dsp\0clk_dsp_iop\0clk_dsp_epp\0clk_dsp_edp\0clk_dsp_edap\0pclk_dsp_cfg\0clk_dsp_pfm\0reserved\0clk_wifi\0clk_test\0clk_dsiphy_24m\0clk_cif_out\0clk_mipicsi_out\0reserved\0reserved\0reserved";
					rockchip,suspend-clkgating-setting = <0x00 0x00>;
					#clock-cells = <0x01>;
					linux,phandle = <0xc4>;
					phandle = <0xc4>;
				};

				gate-clk@0148 {
					compatible = "rockchip,rk3188-gate-clk";
					reg = <0x148 0x04>;
					clocks = <0x65 0x65 0x65 0x65 0x65 0x65 0x65 0x0a 0x0a 0x54 0x0a 0x0a 0x0a 0x0a 0x0a 0x0a>;
					clock-output-names = "pclk_pmu\0pclk_intmem1\0pclk_gpio0\0pclk_pmugrf\0pclk_pmu_niu\0pclk_i2c_pmu\0pclk_pwm_pmu\0reserved\0reserved\0clk_ddrphy4x\0reserved\0reserved\0reserved\0reserved\0reserved\0reserved";
					rockchip,suspend-clkgating-setting = <0x21f 0x21f>;
					#clock-cells = <0x01>;
					linux,phandle = <0x79>;
					phandle = <0x79>;
				};

				gate-clk@014c {
					compatible = "rockchip,rk3188-gate-clk";
					reg = <0x14c 0x04>;
					clocks = <0x6d 0x6e 0x0a 0x0a 0x0a 0x0a 0x0a 0x0a 0x0a 0x0a 0x0a 0x0a 0x0a 0x0a 0x0a 0x0a>;
					clock-output-names = "aclk_core_niu\0pclk_core_niu\0reserved\0reserved\0reserved\0reserved\0reserved\0reserved\0a_dsp_edp_perf\0reserved\0reserved\0reserved\0reserved\0reserved\0reserved\0reserved";
					rockchip,suspend-clkgating-setting = <0x03 0x03>;
					#clock-cells = <0x01>;
					linux,phandle = <0x78>;
					phandle = <0x78>;
				};

				gate-clk@0150 {
					compatible = "rockchip,rk3188-gate-clk";
					reg = <0x150 0x04>;
					clocks = <0x0a 0x0c 0x0c 0x59 0x6f 0x08 0x0d 0x6f 0x08 0x59 0x59 0x59 0x59 0x59 0x5a 0x5a 0x0a 0x0a>;
					clock-output-names = "reserved\0aclk_intmem0\0aclk_dmac\0hclk_rom\0pclk_ddrupctl\0clk_ddr_upctl\0pclk_ddrmon\0hclk_i2s0_8ch\0hclk_i2s1_2ch\0hclk_i2s2_8ch\0hclk_crypto_m\0hclk_crypto_s\0pclk_efuse_0\0pclk_efuse_1\0reserved\0reserved";
					rockchip,suspend-clkgating-setting = <0x7a 0x7a>;
					#clock-cells = <0x01>;
					linux,phandle = <0x77>;
					phandle = <0x77>;
				};

				gate-clk@0154 {
					compatible = "rockchip,rk3188-gate-clk";
					reg = <0x154 0x04>;
					clocks = <0x5a 0x5a 0x5a 0x5a 0x5a 0x5a 0x5a 0x5a 0x5a 0x5a 0x5a 0x5a 0x5a 0x5a 0x5a 0x0a>;
					clock-output-names = "pclk_i2c1\0pclk_i2c2\0pclk_i2c3\0pclk_wdt\0pclk_timer\0pclk_spi\0pclk_pwm1\0pclk_gpio1\0pclk_gpio2\0pclk_gpio3\0pclk_uart0\0pclk_uart1\0pclk_uart2\0pclk_tsadc\0pclk_saradc\0reserved";
					rockchip,suspend-clkgating-setting = <0x10 0x10>;
					#clock-cells = <0x01>;
					linux,phandle = <0x7a>;
					phandle = <0x7a>;
				};

				gate-clk@0158 {
					compatible = "rockchip,rk3188-gate-clk";
					reg = <0x158 0x04>;
					clocks = <0x5a 0x0c 0x6f 0x08 0x6f 0x07 0x6f 0x07 0x6f 0x07 0x6f 0x07 0x6f 0x07 0x6f 0x07 0x6f 0x07 0x0a 0x6f 0x07 0x6f 0x07 0x0a 0x6f 0x07 0x0a>;
					clock-output-names = "pclk_grf\0aclk_bus_niu\0pclk_mshchniu\0pclk_top_niu\0pclk_ddrphy\0pclk_cru\0pclk_acodecphy\0reserved\0pclk_hdmiphy\0pclk_vdacphy\0reserved\0p_mipi_dsi_phy\0p_mipi_csi_phy\0reserved\0pclk_usbgrf\0reserved";
					rockchip,suspend-clkgating-setting = <0x3f 0x3f>;
					#clock-cells = <0x01>;
					linux,phandle = <0x7b>;
					phandle = <0x7b>;
				};

				gate-clk@015c {
					compatible = "rockchip,rk3188-gate-clk";
					reg = <0x15c 0x04>;
					clocks = <0x70 0x70 0x70 0x70 0x2c 0x71 0x70 0x70 0x70 0x70 0x70 0x2c 0x70 0x71 0x0a 0x0a>;
					clock-output-names = "hclk_sdmmc\0hclk_sdio\0hclk_emmc\0hclk_nandc\0aclk_gmac\0pclk_gmac\0hclk_host0\0hclk_host0_arb\0hclk_otg\0hclk_otg_pmu\0hclk_sfc\0aclk_peri_niu\0hclk_peri_niu\0pclk_peri_niu\0reserved\0reserved";
					rockchip,suspend-clkgating-setting = <0x00 0x00>;
					#clock-cells = <0x01>;
					linux,phandle = <0x7c>;
					phandle = <0x7c>;
				};

				gate-clk@0160 {
					compatible = "rockchip,rk3188-gate-clk";
					reg = <0x160 0x04>;
					clocks = <0x51 0x51 0x51 0x51 0x0a 0x0a 0x0a 0x51 0x6a 0x6a 0x6a 0x6a 0x6a 0x51 0x0a 0x0a>;
					clock-output-names = "clk_dsp_sys_wd\0clk_dsp_epp_wd\0clk_dsp_edp_wd\0clk_dsp_iop_wd\0p_dsp_iop_niu\0p_dsp_epp_niu\0a_dsp_edp_niu\0p_dsp_dbg_niu\0p_dsp_cfg_niu\0p_dsp_pfm_mon\0pclk_intc\0pclk_dsp_grf\0pclk_mailbox\0clk_dsp_free\0a_dsp_edap_niu\0a_dsp_epp_perf";
					rockchip,suspend-clkgating-setting = <0x00 0x00>;
					#clock-cells = <0x01>;
					linux,phandle = <0x7d>;
					phandle = <0x7d>;
				};

				gate-clk@0164 {
					compatible = "rockchip,rk3188-gate-clk";
					reg = <0x164 0x04>;
					clocks = <0x35 0x36 0x35 0x36 0x0a 0x0a 0x36 0x72 0x36 0x72 0x36 0x72 0x72 0x0a 0x0a 0x0a>;
					clock-output-names = "aclk_vio0_pre\0aclk_vio1_pre\0hclk_vio_pre\0pclk_vio_pre\0reserved\0reserved\0aclk_cif1\0hclk_cif1\0aclk_cif2\0hclk_cif2\0aclk_cif3\0hclk_cif3\0hclk_cvbs\0reserved\0reserved\0reserved";
					rockchip,suspend-clkgating-setting = <0x00 0x00>;
					#clock-cells = <0x01>;
					linux,phandle = <0xce>;
					phandle = <0xce>;
				};

				gate-clk@0168 {
					compatible = "rockchip,rk3188-gate-clk";
					reg = <0x168 0x04>;
					clocks = <0x35 0x72 0x35 0x72 0x36 0x72 0x36 0x72 0x73 0x73 0x74 0x06 0x72 0x36 0x0a 0x0a 0x0a>;
					clock-output-names = "aclk_vop\0hclk_vop\0aclk_iep\0hclk_iep\0aclk_rga\0hclk_rga\0aclk_cif0\0hclk_cif0\0pclk_mipi_dsi0\0pclk_hdmi_ctrl\0pclk_isp\0hclk_isp_ctrl\0aclk_isp\0reserved\0reserved\0reserved";
					rockchip,suspend-clkgating-setting = <0x00 0x00>;
					#clock-cells = <0x01>;
					linux,phandle = <0xc3>;
					phandle = <0xc3>;
				};

				gate-clk@016c {
					compatible = "rockchip,rk3188-gate-clk";
					reg = <0x16c 0x04>;
					clocks = <0x49 0x4b 0x75 0x75 0x0a 0x0a 0x0a 0x0a 0x04 0x76 0x0a 0x0a 0x0a 0x0a 0x0a 0x0a>;
					clock-output-names = "aclk_rkvdec_pre\0aclk_vpu_pre\0hclk_rkvdec_pre\0hclk_vpu\0aclk_rkvdec_niu\0hclk_rkvdec_niu\0aclk_vpu_niu\0reserved\0aclk_rkvenc_pre\0hclk_rkvenc_pre\0aclk_rkvenc_niu\0hclk_rkvenc_niu\0reserved\0reserved\0reserved\0reserved";
					rockchip,suspend-clkgating-setting = <0x00 0x00>;
					#clock-cells = <0x01>;
					linux,phandle = <0x7e>;
					phandle = <0x7e>;
				};
			};
		};
	};

	chosen {
		bootargs = "user_debug=31 rockchip_jtag noinitrd root=/dev/mtdblock3 rootfstype=squashfs";
	};

	aliases {
		i2c0 = "/i2c@20000000";
		i2c1 = "/i2c@10240000";
		i2c2 = "/i2c@10250000";
		i2c3 = "/i2c@10260000";
		serial0 = "/serial@10230000";
		serial1 = "/serial@10220000";
		serial2 = "/serial@10210000";
		spi0 = "/spi@10270000";
		cif0 = "/cif_cif@30060000";
		cif1 = "/cif_cif@30080000";
		cif2 = "/cif_cif@30090000";
		cif3 = "/cif_cif@300a0000";
	};

	memory {
		device_type = "memory";
		reg = <0x60000000 0x8000000>;
	};

	ddr_timing {
		compatible = "rockchip,ddr-timing";
		dram_spd_bin = <0x15>;
		sr_idle = <0x03>;
		pd_idle = <0x20>;
		dram_dll_disb_freq = <0x12c>;
		phy_dll_disb_freq = <0x190>;
		dram_odt_disb_freq = <0x14d>;
		phy_odt_disb_freq = <0x14d>;
		ddr3_drv = <0x00>;
		ddr3_odt = <0x40>;
		lpddr3_drv = <0x01>;
		lpddr3_odt = <0x03>;
		lpddr2_drv = <0x01>;
		phy_ddr3_clk_drv = <0x12>;
		phy_ddr3_cmd_drv = <0x15>;
		phy_ddr3_dqs_drv = <0x15>;
		phy_ddr3_odt = <0x02>;
		phy_lp23_clk_drv = <0x13>;
		phy_lp23_cmd_drv = <0x16>;
		phy_lp23_dqs_drv = <0x16>;
		phy_lp3_odt = <0x02>;
	};

	cpus {
		#address-cells = <0x01>;
		#size-cells = <0x00>;

		cpu@f00 {
			device_type = "cpu";
			compatible = "arm,cortex-a7";
			reg = <0xf00>;
		};
	};

	cpu_axi_bus {
		compatible = "rockchip,cpu_axi_bus";
		#address-cells = <0x01>;
		#size-cells = <0x01>;
		ranges;

		qos {
			#address-cells = <0x01>;
			#size-cells = <0x01>;
			ranges;

			cpu {
				reg = <0x31000000 0x20>;
			};

			dsp {
				reg = <0x31010000 0x20>;
			};

			rkvenc_r0 {
				reg = <0x31020000 0x20>;
			};

			rkvenc_r1 {
				reg = <0x31020100 0x20>;
			};

			rkvenc_w0 {
				reg = <0x31020200 0x20>;
			};

			rkvenc_w1 {
				reg = <0x31020300 0x20>;
			};

			rkvdec_r {
				reg = <0x31030000 0x20>;
			};

			rkvdec_w {
				reg = <0x31030080 0x20>;
			};

			vpu {
				reg = <0x31030100 0x20>;
			};

			vop {
				reg = <0x31050000 0x20>;
				rockchip,priority = <0x03 0x03>;
			};

			iep {
				reg = <0x31050080 0x20>;
			};

			rga_w {
				reg = <0x31050100 0x20>;
			};

			cif0 {
				reg = <0x31050180 0x20>;
				rockchip,priority = <0x03 0x03>;
			};

			rga_r {
				reg = <0x31050200 0x20>;
			};

			isp_r {
				reg = <0x31050280 0x20>;
				rockchip,priority = <0x03 0x03>;
			};

			isp_w0 {
				reg = <0x31050300 0x20>;
				rockchip,priority = <0x03 0x03>;
			};

			isp_w1 {
				reg = <0x31050380 0x20>;
				rockchip,priority = <0x03 0x03>;
			};

			cif1 {
				reg = <0x31050400 0x20>;
				rockchip,priority = <0x03 0x03>;
			};

			cif2 {
				reg = <0x31050480 0x20>;
				rockchip,priority = <0x03 0x03>;
			};

			cif3 {
				reg = <0x31050500 0x20>;
				rockchip,priority = <0x03 0x03>;
			};

			dma {
				reg = <0x31060080 0x20>;
			};

			crypto {
				reg = <0x31060100 0x20>;
			};

			emmc {
				reg = <0x31080000 0x20>;
			};

			gmac {
				reg = <0x31080080 0x20>;
			};

			nandc {
				reg = <0x31080100 0x20>;
			};

			sdio {
				reg = <0x31080180 0x20>;
			};

			sdmmc {
				reg = <0x31080200 0x20>;
			};

			usbhost {
				reg = <0x31080280 0x20>;
			};

			sfc {
				reg = <0x31080300 0x20>;
			};

			usbotg {
				reg = <0x31080400 0x20>;
			};
		};
	};

	arm-pmu {
		compatible = "arm,cortex-a7-pmu";
		interrupts = <0x00 0x4c 0x04>;
	};

	timer {
		compatible = "arm,armv7-timer";
		interrupts = <0x01 0x0d 0xf04 0x01 0x0e 0xf04>;
		clock-frequency = <0x16e3600>;
	};

	amba {
		#address-cells = <0x01>;
		#size-cells = <0x01>;
		compatible = "arm,amba-bus";
		interrupt-parent = <0x02>;
		ranges;

		pdma@102a0000 {
			compatible = "arm,pl330\0arm,primecell";
			reg = <0x102a0000 0x4000>;
			clocks = <0x77 0x02>;
			clock-names = "apb_pclk";
			interrupts = <0x00 0x00 0x04>;
			#dma-cells = <0x01>;
			linux,phandle = <0x80>;
			phandle = <0x80>;
		};
	};

	clocks-init {
		compatible = "rockchip,clocks-init";
		rockchip,clocks-init-parent = <0x0c 0x08 0x2c 0x08 0x32 0x08 0x31 0x08 0x44 0x56 0x21 0x57 0x2d 0x07>;
		rockchip,clocks-init-rate = <0x08 0x46cf7100 0x06 0x2faf0800 0x51 0x179a7b00 0x0c 0x8f0d180 0x59 0x8f0d180 0x5a 0x47868c0 0x2c 0x8f0d180 0x70 0x8f0d180 0x71 0x47868c0 0x35 0x11e1a300 0x36 0x11e1a300 0x72 0x47868c0 0x73 0x47868c0 0x49 0x11e1a300 0x4b 0x11e1a300 0x4a 0x11e1a300 0x05 0x11e1a300 0x04 0x11e1a300 0x4c 0x11e1a300 0x1a 0x8f0d180 0x34 0x8f0d180 0x0e 0x2367b880 0x14 0x2367b880 0x17 0x2367b880 0x1e 0x11b3dc40 0x22 0x11b3dc40 0x25 0x11b3dc40 0x45 0x11e1a300>;
		rockchip,clocks-uboot-has-init = <0x41>;
		rockchip,set_div_for_pll_init;
	};

	clocks-enable {
		compatible = "rockchip,clocks-enable";
		clocks = <0x07 0x09 0x08 0x06 0x6e 0x6d 0x78 0x00 0x78 0x01 0x79 0x09 0x6f 0x06 0x77 0x01 0x77 0x02 0x77 0x03 0x77 0x04 0x77 0x05 0x77 0x06 0x77 0x0c 0x77 0x0d 0x7a 0x04 0x7b 0x00 0x7b 0x01 0x7b 0x02 0x7b 0x03 0x7b 0x04 0x7b 0x05 0x7b 0x0e 0x7c 0x0b 0x7c 0x0c 0x7c 0x0d 0x7c 0x09 0x79 0x00 0x79 0x01 0x79 0x03 0x79 0x04 0x78 0x08 0x7d 0x04 0x7d 0x05 0x7d 0x06 0x7d 0x07 0x7d 0x08 0x7d 0x09 0x7d 0x0a 0x7d 0x0b 0x7d 0x0c 0x7d 0x0e 0x7d 0x0f 0x7e 0x04 0x7e 0x05 0x7e 0x06 0x7e 0x0a 0x7e 0x0b 0x6f 0x09 0x6f 0x0a 0x7f 0x03>;
	};

	dvfs {

		vd-logic {
			regulator_name = "vdd_arm";

			pd_core {

				clk_core {
					operating-points = <0x639c0 0xee098 0x927c0 0xee098 0xc7380 0xfa3e8 0xf6180 0x118c30>;
					status = "okay";
					tsadc-ch = <0x00>;
					temp-limit-enable = <0x01>;
					target-temp = <0x5f>;
					min_temp_limit = <0x927c0>;
					normal-temp-limit = <0x03 0x17700 0x06 0x23280 0x09 0x2ee00 0x0f 0x5dc00>;
					performance-temp-limit = <0x64 0xc7380>;
					lkg_adjust_volt_en = <0x01>;
					channel = <0x00>;
					def_table_lkg = <0x06>;
					min_adjust_freq = <0x639c0>;
					lkg_adjust_volt_table = <0x3c 0x61a8>;
				};
			};

			pd_ddr {

				clk_ddr {
					operating-points = <0x61a80 0xee098 0x927c0 0x10c8e0 0xc3500 0x118c30>;
					freq-table = <0x20000 0x61a80 0x01 0x927c0 0x2000 0xc3500>;
					lkg_adjust_volt_en = <0x01>;
					channel = <0x00>;
					def_table_lkg = <0x06>;
					min_adjust_freq = <0x493e0>;
					lkg_adjust_volt_table = <0x3c 0xc350>;
					status = "okay";
				};
			};

			pd_dsp {

				clk_dsp {
					operating-points = <0x186a0 0xee098 0x493e0 0xfa3e8 0x61a80 0x10c8e0 0x927c0 0x11edd8>;
					skip_adjusting_volt = <0x01>;
					status = "okay";
					lkg_adjust_volt_en = <0x01>;
					channel = <0x00>;
					def_table_lkg = <0x06>;
					min_adjust_freq = <0x186a0>;
					lkg_adjust_volt_table = <0x3c 0x61a8>;
				};
			};

			pd_isp {

				clk_isp {
					operating-points = <0x61a80 0xee098 0x75300 0xfa3e8 0x91050 0x10c8e0>;
					skip_adjusting_volt = <0x01>;
					lkg_adjust_volt_en = <0x01>;
					channel = <0x00>;
					def_table_lkg = <0x06>;
					min_adjust_freq = <0x493e0>;
					lkg_adjust_volt_table = <0x3c 0x61a8>;
					status = "disabled";
				};
			};

			pd_venc {

				clk_venc_core {
					operating-points = <0x493e0 0xee098 0x61a80 0xfa3e8 0x75300 0x10c8e0>;
					skip_adjusting_volt = <0x01>;
					lkg_adjust_volt_en = <0x00>;
					channel = <0x00>;
					status = "disabled";
				};
			};
		};
	};

	sram@10080000 {
		compatible = "mmio-sram";
		reg = <0x10080000 0x2000>;
		map-exec;
		linux,phandle = <0x01>;
		phandle = <0x01>;
	};

	i2s0@10110000 {
		compatible = "rockchip-i2s";
		reg = <0x10110000 0x1000>;
		i2s-id = <0x00>;
		clocks = <0x13 0x5b 0x77 0x07>;
		clock-names = "i2s_clk\0i2s_mclk\0i2s_hclk";
		interrupts = <0x00 0x17 0x04>;
		dmas = <0x80 0x0b 0x80 0x0c>;
		#dma-cells = <0x02>;
		dma-names = "tx\0rx";
		pinctrl-names = "default\0sleep";
		pinctrl-0 = <0x81 0x82 0x83 0x84 0x85 0x86 0x87 0x88 0x89>;
		pinctrl-1 = <0x8a>;
		status = "disabled";
	};

	i2s1@10120000 {
		compatible = "rockchip-i2s";
		reg = <0x10120000 0x1000>;
		i2s-id = <0x01>;
		clocks = <0x5c 0x77 0x08>;
		clock-names = "i2s_clk\0i2s_hclk";
		interrupts = <0x00 0x18 0x04>;
		dmas = <0x80 0x00 0x80 0x01>;
		#dma-cells = <0x02>;
		dma-names = "tx\0rx";
		status = "okay";
		linux,phandle = <0xf2>;
		phandle = <0xf2>;
	};

	i2s2@10130000 {
		compatible = "rockchip-i2s";
		reg = <0x10130000 0x1000>;
		i2s-id = <0x02>;
		clocks = <0x5d 0x77 0x09>;
		clock-names = "i2s_clk\0i2s_hclk";
		interrupts = <0x00 0x19 0x04>;
		dmas = <0x80 0x0f 0x80 0x10>;
		#dma-cells = <0x02>;
		dma-names = "tx\0rx";
		pinctrl-names = "default\0sleep";
		pinctrl-0 = <0x8b 0x8c 0x8d 0x8e>;
		pinctrl-1 = <0x8f>;
		status = "disabled";
	};

	crypto@10140000 {
		compatible = "rockchip-crypto";
		reg = <0x10140000 0x10000>;
		interrupts = <0x00 0x1a 0x04>;
		interrupt-names = "irq_crypto";
		clocks = <0x1a 0x77 0x0b 0x77 0x0a>;
		clock-names = "clk_crypto\0hclk_crypto\0aclk_crypto";
		status = "disabled";
	};

	serial@10210000 {
		compatible = "rockchip,serial";
		reg = <0x10210000 0x100>;
		interrupts = <0x00 0x2e 0x04>;
		clock-frequency = <0x2367b880>;
		clocks = <0x90 0x7a 0x0c>;
		clock-names = "sclk_uart\0pclk_uart";
		reg-shift = <0x02>;
		reg-io-width = <0x04>;
		dmas = <0x80 0x06 0x80 0x07>;
		#dma-cells = <0x02>;
		pinctrl-names = "default";
		pinctrl-0 = <0x91>;
		status = "disabled";
	};

	serial@10220000 {
		compatible = "rockchip,serial";
		reg = <0x10220000 0x100>;
		interrupts = <0x00 0x2d 0x04>;
		clock-frequency = <0x2367b880>;
		clocks = <0x92 0x7a 0x0b>;
		clock-names = "sclk_uart\0pclk_uart";
		reg-shift = <0x02>;
		reg-io-width = <0x04>;
		dmas = <0x80 0x04 0x80 0x05>;
		#dma-cells = <0x02>;
		pinctrl-names = "default";
		pinctrl-0 = <0x93 0x94 0x95>;
		status = "disabled";
	};

	serial@10230000 {
		compatible = "rockchip,serial";
		reg = <0x10230000 0x100>;
		interrupts = <0x00 0x2c 0x04>;
		clock-frequency = <0x2367b880>;
		clocks = <0x96 0x7a 0x0a>;
		clock-names = "sclk_uart\0pclk_uart";
		reg-shift = <0x02>;
		reg-io-width = <0x04>;
		dmas = <0x80 0x02 0x80 0x03>;
		#dma-cells = <0x02>;
		pinctrl-names = "default";
		pinctrl-0 = <0x97>;
		status = "ok";
	};

	fiq-debugger {
		compatible = "rockchip,fiq-debugger";
		rockchip,serial-id = <0x02>;
		rockchip,signal-irq = <0x9f>;
		rockchip,wake-irq = <0x00>;
		rockchip,irq-mode-enable = <0x00>;
		rockchip,baudrate = <0x16e360>;
		pinctrl-names = "default";
		pinctrl-0 = <0x98>;
		status = "okay";
	};

	i2c@20000000 {
		compatible = "rockchip,rv1108-i2c";
		reg = <0x20000000 0x1000>;
		interrupts = <0x00 0x1e 0x04>;
		rockchip,grf = <0x99>;
		#address-cells = <0x01>;
		#size-cells = <0x00>;
		clocks = <0x28 0x79 0x05>;
		clock-names = "i2c\0pclk";
		pinctrl-names = "default";
		pinctrl-0 = <0x9a>;
		status = "okay";
		i2c-scl-rising-time-ns = <0x113>;
		i2c-scl-falling-time-ns = <0x10>;
		clock-frequency = <0x61a80>;
		nack-retry = <0x01>;

		rk816@1a {
			reg = <0x1a>;
			status = "okay";
			compatible = "rockchip,rk816";
			gpios = <0x9b 0x0c 0x00 0x9b 0x0d 0x01>;
			rk816,system-power-controller;
			rk816,support_dc_chg = <0x00>;

			regulators {
				#address-cells = <0x01>;
				#size-cells = <0x00>;

				regulator@0 {
					reg = <0x00>;
					regulator-compatible = "RK816_DCDC1";
					regulator-always-on;
					regulator-boot-on;
					regulator-name = "vdd_arm";
					regulator-min-microvolt = <0xaae60>;
					regulator-max-microvolt = <0x16e360>;
					regulator-initial-mode = <0x01>;
					regulator-initial-state = <0x03>;

					regulator-state-mem {
						regulator-state-mode = <0x02>;
						regulator-state-enabled;
						regulator-state-uv = <0xdbba0>;
					};
				};

				regulator@1 {
					reg = <0x01>;
					regulator-compatible = "RK816_DCDC2";
					regulator-always-on;
					regulator-boot-on;
					regulator-name = "vcc_22";
					regulator-min-microvolt = <0x2191c0>;
					regulator-max-microvolt = <0x2191c0>;
					regulator-initial-mode = <0x01>;
					regulator-initial-state = <0x03>;

					regulator-state-mem {
						regulator-state-enabled;
						regulator-state-uv = <0x124f80>;
					};
				};

				regulator@2 {
					reg = <0x02>;
					regulator-compatible = "RK816_DCDC3";
					regulator-always-on;
					regulator-boot-on;
					regulator-name = "vcc_ddr";
					regulator-min-microvolt = <0x124f80>;
					regulator-max-microvolt = <0x124f80>;
					regulator-initial-mode = <0x01>;
					regulator-initial-state = <0x03>;

					regulator-state-mem {
						regulator-state-mode = <0x02>;
						regulator-state-enabled;
						regulator-state-uv = <0x124f80>;
					};
				};

				regulator@3 {
					reg = <0x03>;
					regulator-compatible = "RK816_DCDC4";
					regulator-always-on;
					regulator-boot-on;
					regulator-name = "vcc_io";
					regulator-min-microvolt = <0x325aa0>;
					regulator-max-microvolt = <0x325aa0>;
					regulator-initial-mode = <0x01>;
					regulator-initial-state = <0x03>;
					linux,phandle = <0xef>;
					phandle = <0xef>;

					regulator-state-mem {
						regulator-state-mode = <0x02>;
						regulator-state-enabled;
						regulator-state-uv = <0x325aa0>;
					};
				};

				regulator@4 {
					reg = <0x04>;
					regulator-compatible = "RK816_LDO1";
					regulator-always-on;
					regulator-boot-on;
					regulator-name = "vdd_10";
					regulator-min-microvolt = <0xf4240>;
					regulator-max-microvolt = <0xf4240>;
					regulator-initial-state = <0x03>;

					regulator-state-mem {
						regulator-state-disabled;
					};
				};

				regulator@5 {
					reg = <0x05>;
					regulator-compatible = "RK816_LDO2";
					regulator-boot-on;
					regulator-name = "vcc_18";
					regulator-min-microvolt = <0x1b7740>;
					regulator-max-microvolt = <0x1b7740>;
					regulator-initial-state = <0x03>;
					regulator-always-on;
					linux,phandle = <0xf0>;
					phandle = <0xf0>;

					regulator-state-mem {
						regulator-state-disabled;
					};
				};

				regulator@6 {
					reg = <0x06>;
					regulator-compatible = "RK816_LDO3";
					regulator-always-on;
					regulator-name = "vdd10_pmu";
					regulator-min-microvolt = <0xf4240>;
					regulator-max-microvolt = <0xf4240>;
					regulator-initial-state = <0x03>;
					regulator-boot-on;

					regulator-state-mem {
						regulator-state-enabled;
						regulator-state-uv = <0xf4240>;
					};
				};

				regulator@7 {
					reg = <0x07>;
					regulator-compatible = "RK816_LDO4";
					regulator-always-on;
					regulator-boot-on;
					regulator-name = "vdd33_pmu";
					regulator-min-microvolt = <0x325aa0>;
					regulator-max-microvolt = <0x325aa0>;
					regulator-initial-state = <0x03>;

					regulator-state-mem {
						regulator-state-enabled;
						regulator-state-uv = <0x325aa0>;
					};
				};

				regulator@8 {
					reg = <0x08>;
					regulator-compatible = "RK816_LDO5";
					regulator-name = "dovdd_cam";
					regulator-min-microvolt = <0x1b7740>;
					regulator-max-microvolt = <0x325aa0>;
					regulator-initial-state = <0x03>;

					regulator-state-mem {
						regulator-state-disabled;
					};
				};

				regulator@9 {
					reg = <0x09>;
					regulator-compatible = "RK816_LDO6";
					regulator-always-on;
					regulator-boot-on;
					regulator-name = "lcd_bl";
					regulator-min-microvolt = <0x1b7740>;
					regulator-max-microvolt = <0x325aa0>;
					regulator-initial-state = <0x03>;

					regulator-state-mem {
						regulator-state-enabled;
						regulator-state-uv = <0x2ab980>;
					};
				};
			};

			rtc {
				status = "okay";
			};

			battery {
				ocv_table = <0xdac 0xdf9 0xe1c 0xe34 0xe50 0xe63 0xe6f 0xe79 0xe82 0xe90 0xe9e 0xeb1 0xec9 0xee6 0xf07 0xf26 0xf3e 0xf60 0xf9a 0xfbe 0x1044>;
				ntc_table = <0x2e054 0x2b9a8 0x294f0 0x27290 0x25224 0x233ac 0x216c4 0x1fbd0 0x1e208 0x1c9d0 0x1b2c4 0x19d48 0x188f8 0x17598 0x1635a 0x15220 0x141cc 0x1325e 0x123c2 0x115e4 0x108ce 0xfc62 0xf0a0 0xe574 0xdade 0xd0d4 0xc756 0xbe46 0xb5b8 0xad8e 0xa5d2 0x9e7a 0x977c 0x90d8 0x8a84 0x848a 0x7ecc 0x795e 0x7436 0x6f4a 0x6a90 0x661c 0x61da 0x5dca 0x59ec 0x5636 0x52b2 0x4f56 0x4c22 0x4916 0x4628 0x4362 0x40ba 0x3e26 0x3bba 0x396c 0x3732 0x3516 0x330e 0x311a 0x2f3a 0x2d78 0x2bc0 0x2a1c 0x288c 0x2710 0x25a1 0x2442 0x22f1 0x21ae 0x2078 0x1f4f 0x1e32 0x1d20 0x1c1a 0x1b1e 0x1a2c 0x1944 0x1865 0x178f 0x16c2 0x15fc 0x153e 0x1487 0x13d8 0x132f 0x128d 0x11f0 0x115a 0x10c9 0x103e 0xfb8 0xf37 0xebb 0xe43 0xdd0 0xd61 0xcf6 0xc8f 0xc2b 0xbcb 0xb6f 0xb15 0xabf 0xa6c 0xa1c 0x9cf 0x984 0x93c 0x8f7 0x8b3 0x873 0x834 0x7f7 0x7bd 0x784 0x74d 0x719 0x6e5 0x6b4 0x684 0x656 0x629 0x5fe 0x5d4 0x5ab 0x584 0x55e 0x539 0x516 0x4f3 0x4d2 0x4b1 0x492 0x473 0x456 0x439 0x41e 0x403 0x3e9 0x3cf 0x3b7 0x39f 0x388 0x371 0x35c 0x347 0x332 0x31e 0x30b 0x2f8 0x2e6 0x2d4 0x2c3 0x2b2 0x2a2 0x292 0x283 0x274 0x265 0x257 0x249 0x23c 0x22f 0x223 0x216>;
				ntc_degree_from = <0x01 0x28>;
				design_capacity = <0x7b2>;
				design_qmax = <0x877>;
				bat_res = <0xa5>;
				max_input_current = <0x7d0>;
				max_chrg_current = <0x640>;
				max_chrg_voltage = <0x1068>;
				max_bat_voltagemV = <0x1068>;
				sleep_enter_current = <0x12c>;
				sleep_exit_current = <0x12c>;
				sleep_filter_current = <0x64>;
				power_off_thresd = <0xdac>;
				zero_algorithm_vol = <0xf6e>;
				fb_temperature = <0x69>;
				sample_res = <0x14>;
				energy_mode = <0x01>;
				max_soc_offset = <0x3c>;
				monitor_sec = <0x05>;
				virtual_power = <0x00>;
				power_dc2otg = <0x00>;
			};
		};

		sensor@19 {
			compatible = "bma2xx_acc";
			reg = <0x19>;
			type = <0x02>;
			irq-gpio = <0x9c 0x15 0x04>;
			irq_enable = <0x00>;
			poll_delay_ms = <0x1e>;
			layout = <0x02>;
			status = "disabled";
		};

		nvp6124@30 {
			status = "disabled";
			compatible = "rockchip,nvp";
			reg = <0x30>;
			device_type = "v4l2-i2c-subdev";
			channels = <0x04>;
			apio_vol = <0xce4>;
			cvbs_mode = "PAL";
			reset-gpio = <0x9c 0x16 0x01>;
			irq-gpio = <0x9c 0x1b 0x00>;
			pinctrl-names = "default\0sleep";
			pinctrl-0 = <0x9d 0x9e>;
			pinctrl-1 = <0x9f 0xa0>;
			linux,phandle = <0xcb>;
			phandle = <0xcb>;
		};

		mpu6500@68 {
			status = "disabled";
			compatible = "invensense,mpu6500";
			reg = <0x68>;
			mpu-int_config = <0x10>;
			mpu-level_shifter = <0x00>;
			mpu-orientation = <0x01 0x00 0x00 0x00 0x01 0x00 0x00 0x00 0x01>;
			orientation-x = <0x01>;
			orientation-y = <0x01>;
			orientation-z = <0x00>;
			support-hw-poweroff = <0x01>;
			mpu-debug = <0x01>;
		};
	};

	i2c@10240000 {
		compatible = "rockchip,rv1108-i2c";
		reg = <0x10240000 0x1000>;
		interrupts = <0x00 0x1f 0x04>;
		rockchip,grf = <0x99>;
		#address-cells = <0x01>;
		#size-cells = <0x00>;
		clocks = <0x29 0x7a 0x00>;
		clock-names = "i2c\0pclk";
		pinctrl-names = "default";
		pinctrl-0 = <0xa1>;
		status = "okay";

		af-controller@0 {
			compatible = "silicon touch,gt9760s-v4l2-i2c-subdev";
			reg = <0x0c>;
			rockchip,vcm-start-current = <0x14>;
			rockchip,vcm-rated-current = <0x64>;
			rockchip,vcm-step-mode = <0x00>;
			linux,phandle = <0xad>;
			phandle = <0xad>;
		};

		camera-module@36 {
			status = "disabled";
			compatible = "omnivision,ov2710-v4l2-i2c-subdev";
			reg = <0x36>;
			device_type = "v4l2-i2c-subdev";
			clocks = <0x4e>;
			clock-names = "clk_cif_out";
			pinctrl-names = "rockchip,camera_default\0rockchip,camera_sleep";
			pinctrl-0 = <0xa2>;
			pinctrl-1 = <0xa3>;
			rockchip,pd-gpio = <0x9c 0x08 0x00>;
			rockchip,pwr-gpio = <0x9c 0x0d 0x00>;
			rockchip,rst-gpio = <0x9c 0x19 0x01>;
			rockchip,camera-module-mclk-name = "clk_cif_out";
			rockchip,camera-module-facing = "back";
			rockchip,camera-module-name = "LA6110PA";
			rockchip,camera-module-len-name = "YM6011P";
			rockchip,camera-module-fov-h = "128";
			rockchip,camera-module-fov-v = "55.7";
			rockchip,camera-module-orientation = <0x00>;
			rockchip,camera-module-iq-flip = <0x00>;
			rockchip,camera-module-iq-mirror = <0x00>;
			rockchip,camera-module-flip = <0x00>;
			rockchip,camera-module-mirror = <0x00>;
			rockchip,camera-module-defrect0 = <0x780 0x438 0x00 0x00 0x780 0x438>;
			rockchip,camera-module-flash-support = <0x00>;
			rockchip,camera-module-mipi-dphy-index = <0x00>;
			linux,phandle = <0xc5>;
			phandle = <0xc5>;
		};

		camera-module@36-1 {
			status = "disabled";
			compatible = "omnivision,ov4689-v4l2-i2c-subdev";
			reg = <0x36>;
			device_type = "v4l2-i2c-subdev";
			clocks = <0x4e>;
			clock-names = "clk_cif_out";
			pinctrl-names = "rockchip,camera_default\0rockchip,camera_sleep";
			pinctrl-0 = <0xa2>;
			pinctrl-1 = <0xa3>;
			rockchip,pd-gpio = <0x9c 0x08 0x01>;
			rockchip,pwr-gpio = <0x9c 0x0d 0x00>;
			rockchip,rst-gpio = <0x9c 0x19 0x01>;
			rockchip,camera-module-mclk-name = "clk_cif_out";
			rockchip,camera-module-facing = "back";
			rockchip,camera-module-name = "LA6111PA";
			rockchip,camera-module-len-name = "YM6011P";
			rockchip,camera-module-fov-h = "116";
			rockchip,camera-module-fov-v = "61";
			rockchip,camera-module-orientation = <0x00>;
			rockchip,camera-module-iq-flip = <0x00>;
			rockchip,camera-module-iq-mirror = <0x00>;
			rockchip,camera-module-flip = <0x00>;
			rockchip,camera-module-mirror = <0x01>;
			rockchip,camera-module-defrect0 = <0xa80 0x5f0 0x00 0x00 0xa80 0x5f0>;
			rockchip,camera-module-flash-support = <0x00>;
			rockchip,camera-module-mipi-dphy-index = <0x00>;
			linux,phandle = <0xc6>;
			phandle = <0xc6>;
		};

		camera-module@1a {
			status = "disabled";
			compatible = "sony,imx323-v4l2-i2c-subdev";
			reg = <0x1a>;
			device_type = "v4l2-i2c-subdev";
			clocks = <0x4e>;
			clock-names = "clk_cif_out";
			pinctrl-names = "rockchip,camera_default\0rockchip,camera_sleep";
			pinctrl-0 = <0xa4 0x9d 0xa5 0x9e 0xa2 0xa6>;
			pinctrl-1 = <0xa7 0x9f 0xa8 0xa0 0xa3 0xa9>;
			rockchip,pd-gpio = <0x9c 0x19 0x01>;
			rockchip,pwr-gpio = <0x9c 0x0d 0x00>;
			rockchip,rst-gpio = <0x9c 0x08 0x01>;
			rockchip,camera-module-mclk-name = "clk_cif_out";
			rockchip,camera-module-facing = "back";
			rockchip,camera-module-name = "LA6114PA";
			rockchip,camera-module-len-name = "YM6011P";
			rockchip,camera-module-fov-h = "122";
			rockchip,camera-module-fov-v = "63";
			rockchip,camera-module-orientation = <0x00>;
			rockchip,camera-module-iq-flip = <0x00>;
			rockchip,camera-module-iq-mirror = <0x00>;
			rockchip,camera-module-flip = <0x00>;
			rockchip,camera-module-mirror = <0x00>;
			rockchip,camera-module-defrect0 = <0x898 0x465 0x30 0x0d 0x780 0x438>;
			rockchip,camera-module-flash-support = <0x00>;
			linux,phandle = <0xc7>;
			phandle = <0xc7>;
		};

		camera-module@60 {
			status = "disabled";
			compatible = "omnivision,ov7251-bw-v4l2-i2c-subdev";
			reg = <0x60>;
			device_type = "v4l2-i2c-subdev";
			clocks = <0x6c>;
			clock-names = "clk_mipicsi_out";
			pinctrl-names = "rockchip,camera_default\0rockchip,camera_sleep";
			pinctrl-0 = <0xaa>;
			pinctrl-1 = <0xab>;
			rockchip,pd-gpio = <0x9c 0x19 0x01>;
			rockchip,camera-module-mclk-name = "clk_mipicsi_out";
			rockchip,camera-module-facing = "back";
			rockchip,camera-module-name = "NAVA";
			rockchip,camera-module-len-name = "FISHEYE";
			rockchip,camera-module-fov-h = "128";
			rockchip,camera-module-fov-v = "55.7";
			rockchip,camera-module-orientation = <0x00>;
			rockchip,camera-module-iq-flip = <0x00>;
			rockchip,camera-module-iq-mirror = <0x00>;
			rockchip,camera-module-flip = <0x00>;
			rockchip,camera-module-mirror = <0x00>;
			rockchip,camera-module-defrect0 = <0x280 0x1e0 0x00 0x00 0x280 0x1e0>;
			rockchip,camera-module-flash-support = <0x00>;
			rockchip,camera-module-mipi-dphy-index = <0x00>;
			linux,phandle = <0xc8>;
			phandle = <0xc8>;
		};

		camera-module@1a-1 {
			status = "disabled";
			compatible = "sony,imx291-v4l2-i2c-subdev";
			reg = <0x1a>;
			device_type = "v4l2-i2c-subdev";
			clocks = <0x4e>;
			clock-names = "clk_cif_out";
			pinctrl-names = "rockchip,camera_default\0rockchip,camera_sleep";
			pinctrl-0 = <0xa2>;
			pinctrl-1 = <0xa3>;
			rockchip,pd-gpio = <0x9c 0x08 0x00>;
			rockchip,pwr-gpio = <0x9c 0x0d 0x00>;
			rockchip,rst-gpio = <0x9c 0x19 0x01>;
			rockchip,camera-module-mclk-name = "clk_cif_out";
			rockchip,camera-module-facing = "back";
			rockchip,camera-module-name = "LA6112PA";
			rockchip,camera-module-len-name = "YM6011P";
			rockchip,camera-module-fov-h = "122";
			rockchip,camera-module-fov-v = "63";
			rockchip,camera-module-orientation = <0x00>;
			rockchip,camera-module-iq-flip = <0x00>;
			rockchip,camera-module-iq-mirror = <0x00>;
			rockchip,camera-module-flip = <0x00>;
			rockchip,camera-module-mirror = <0x00>;
			rockchip,camera-module-defrect0 = <0x780 0x438 0x00 0x00 0x780 0x438>;
			rockchip,camera-module-flash-support = <0x00>;
			rockchip,camera-module-mipi-dphy-index = <0x00>;
		};

		camera-module@37 {
			status = "disabled";
			compatible = "samsung,s5k4h8-v4l2-i2c-subdev";
			reg = <0x10>;
			device_type = "v4l2-i2c-subdev";
			clocks = <0x6c>;
			clock-names = "clk_mipicsi_out";
			pinctrl-names = "rockchip,camera_default\0rockchip,camera_sleep";
			pinctrl-0 = <0xa2>;
			pinctrl-1 = <0xa3>;
			rockchip,pd-gpio = <0x9c 0x08 0x01>;
			rockchip,dvdd-gpio = <0xac 0x18 0x00>;
			rockchip,dovdd-gpio = <0xac 0x1b 0x00>;
			rockchip,rst-gpio = <0x9c 0x19 0x01>;
			rockchip,camera-module-mclk-name = "clk_mipicsi_out";
			rockchip,camera-module-regulator-names = "avdd_cam";
			rockchip,camera-module-regulator-voltages = <0x2ab980>;
			rockchip,camera-module-facing = "back";
			rockchip,camera-module-name = "LA6110PA";
			rockchip,camera-module-len-name = "YM6011P";
			rockchip,camera-module-fov-h = "128";
			rockchip,camera-module-fov-v = "55.7";
			rockchip,camera-module-orientation = <0x00>;
			rockchip,camera-module-iq-flip = <0x00>;
			rockchip,camera-module-iq-mirror = <0x00>;
			rockchip,camera-module-flip = <0x00>;
			rockchip,camera-module-mirror = <0x00>;
			rockchip,camera-module-defrect0 = <0xcc0 0x990 0x00 0x00 0xcc0 0x990>;
			rockchip,camera-module-flash-support = <0x00>;
			rockchip,camera-module-mipi-dphy-index = <0x00>;
			rockchip,af-ctrl = <0xad>;
		};

		camera-module@36-2 {
			status = "disabled";
			compatible = "omnivision,ov5695-v4l2-i2c-subdev";
			reg = <0x36>;
			device_type = "v4l2-i2c-subdev";
			clocks = <0x4e>;
			clock-names = "clk_cif_out";
			pinctrl-names = "rockchip,camera_default\0rockchip,camera_sleep";
			pinctrl-0 = <0xa2>;
			pinctrl-1 = <0xa3>;
			rockchip,pd-gpio = <0x9c 0x08 0x01>;
			rockchip,pwr-gpio = <0x9c 0x0d 0x00>;
			rockchip,rst-gpio = <0x9c 0x19 0x01>;
			rockchip,camera-module-mclk-name = "clk_cif_out";
			rockchip,camera-module-facing = "back";
			rockchip,camera-module-name = "D1741";
			rockchip,camera-module-len-name = "YM6011P";
			rockchip,camera-module-fov-h = "128";
			rockchip,camera-module-fov-v = "55.7";
			rockchip,camera-module-orientation = <0x00>;
			rockchip,camera-module-iq-flip = <0x00>;
			rockchip,camera-module-iq-mirror = <0x00>;
			rockchip,camera-module-flip = <0x00>;
			rockchip,camera-module-mirror = <0x00>;
			rockchip,camera-module-defrect0 = <0xa20 0x798 0x00 0x00 0xa20 0x798>;
			rockchip,camera-module-defrect1 = <0xa00 0x5a0 0x00 0x00 0xa00 0x5a0>;
			rockchip,camera-module-flash-support = <0x00>;
			rockchip,camera-module-mipi-dphy-index = <0x00>;
		};
	};

	i2c@10250000 {
		compatible = "rockchip,rv1108-i2c";
		reg = <0x10250000 0x1000>;
		interrupts = <0x00 0x20 0x04>;
		rockchip,grf = <0x99>;
		#address-cells = <0x01>;
		#size-cells = <0x00>;
		clocks = <0x2a 0x7a 0x01>;
		clock-names = "i2c\0pclk";
		pinctrl-names = "default";
		pinctrl-0 = <0xae>;
		status = "okay";
	};

	i2c@10260000 {
		compatible = "rockchip,rv1108-i2c";
		reg = <0x10260000 0x1000>;
		interrupts = <0x00 0x21 0x04>;
		rockchip,grf = <0x99>;
		#address-cells = <0x01>;
		#size-cells = <0x00>;
		clocks = <0x2b 0x7a 0x02>;
		clock-names = "i2c\0pclk";
		pinctrl-names = "default";
		pinctrl-0 = <0xaf>;
		status = "okay";
	};

	spi@10270000 {
		compatible = "rockchip,rockchip-spi";
		reg = <0x10270000 0x1000>;
		interrupts = <0x00 0x25 0x04>;
		#address-cells = <0x01>;
		#size-cells = <0x00>;
		rockchip,spi-src-clk = <0x00>;
		num-cs = <0x01>;
		clocks = <0x1b 0x7a 0x05>;
		clock-names = "spi\0pclk_spi0";
		dmas = <0x80 0x08 0x80 0x09>;
		#dma-cells = <0x02>;
		status = "okay";
		max-freq = <0x2dc6c00>;
		dma-names = "tx\0rx";
		pinctrl-names = "default";
		pinctrl-0 = <0xb0 0xb1 0xb2 0xb3>;

		spi_imu@00 {
			compatible = "rockchip,spidev";
			reg = <0x00>;
			spi-max-frequency = "\0I>";
		};
	};

	pwm@10280000 {
		compatible = "rockchip,rk-pwm";
		reg = <0x10280000 0x10>;
		interrupts = <0x00 0x26 0x04>;
		#pwm-cells = <0x02>;
		pinctrl-names = "default";
		pinctrl-0 = <0xb4>;
		clocks = <0xb5 0x0a 0x7a 0x06>;
		clock-names = "pwm\0pclk";
		status = "disabled";
	};

	pwm@10280010 {
		compatible = "rockchip,rk-pwm";
		reg = <0x10280010 0x10>;
		interrupts = <0x00 0x26 0x04>;
		#pwm-cells = <0x02>;
		pinctrl-names = "default";
		pinctrl-0 = <0xb6>;
		clocks = <0xb5 0x0a 0x7a 0x06>;
		clock-names = "pwm\0pclk";
		status = "disabled";
	};

	pwm@10280020 {
		compatible = "rockchip,rk-pwm";
		reg = <0x10280020 0x10>;
		interrupts = <0x00 0x26 0x04>;
		#pwm-cells = <0x02>;
		pinctrl-names = "default";
		pinctrl-0 = <0xb7>;
		clocks = <0xb5 0x0a 0x7a 0x06>;
		clock-names = "pwm\0pclk";
		status = "disabled";
	};

	pwm@10280030 {
		compatible = "rockchip,rk-pwm";
		reg = <0x10280030 0x10>;
		interrupts = <0x00 0x26 0x04>;
		#pwm-cells = <0x02>;
		pinctrl-names = "default";
		pinctrl-0 = <0xb8>;
		clocks = <0xb5 0x0a 0x7a 0x06>;
		clock-names = "pwm\0pclk";
		status = "disabled";
	};

	syscon@10300000 {
		compatible = "rockchip,rv1108-grf\0rockchip,grf\0syscon";
		reg = <0x10300000 0x1000>;
		linux,phandle = <0x99>;
		phandle = <0x99>;
	};

	syscon@20060000 {
		compatible = "rockchip,rv1108-pmugrf\0rockchip,pmugrf\0syscon";
		reg = <0x20060000 0x1000>;
		linux,phandle = <0xe1>;
		phandle = <0xe1>;
	};

	syscon@202a0000 {
		compatible = "rockchip,rv1108-usbgrf\0rockchip,usbgrf\0syscon";
		reg = <0x202a0000 0x1000>;
		linux,phandle = <0xde>;
		phandle = <0xde>;
	};

	timer@10350000 {
		compatible = "rockchip,timer";
		reg = <0x10350000 0x20>;
		interrupts = <0x00 0x23 0x04>;
		rockchip,broadcast = <0x01>;
	};

	wdt@10360000 {
		compatible = "rockchip,watch dog";
		reg = <0x10360000 0x100>;
		clocks = <0x7a 0x03>;
		clock-names = "pclk_wdt";
		interrupts = <0x00 0x22 0x04>;
		rockchip,irq = <0x00>;
		rockchip,timeout = <0x05>;
		rockchip,atboot = <0x00>;
		rockchip,debug = <0x00>;
		status = "okay";
	};

	tsadc@10370000 {
		compatible = "rockchip,rv1108-tsadc";
		reg = <0x10370000 0x100>;
		interrupts = <0x00 0x2f 0x04>;
		clock-frequency = <0xb71b0>;
		clocks = <0x5e 0x7a 0x0d>;
		clock-names = "tsadc\0pclk_tsadc";
		pinctrl-names = "default";
		pinctrl-0 = <0xb9>;
		tsadc-ht-temp = <0x78>;
		tsadc-ht-reset-cru = <0x01>;
		tsadc-ht-pull-gpio = <0x00>;
		status = "okay";
	};

	adc@1038c000 {
		compatible = "rockchip,saradc";
		reg = <0x1038c000 0x100>;
		interrupts = <0x00 0x04 0x04>;
		#io-channel-cells = <0x01>;
		io-channel-ranges;
		rockchip,adc-vref = <0x708>;
		clock-frequency = <0xf4240>;
		clocks = <0xb5 0x0c 0x7a 0x0e>;
		clock-names = "saradc\0pclk_saradc";
		status = "okay";
		linux,phandle = <0xba>;
		phandle = <0xba>;

		battery_value {
			compatible = "rockchip,rv1108_battery";
			io-channels = <0xba 0x02>;
			battery-levels = <0xed8 0xf0d 0xf10 0xf13 0xf16 0xf19 0xf1c 0xf1f 0xf22 0xf25 0xf28 0xf2b 0xf2e 0xd3d 0xf34 0xf37 0xf3a 0xf3d 0xf40 0xf43 0xf46 0xf49 0xf4c 0xf4f 0xf52 0xf55 0xf58 0xf5b 0xf5e 0xf61 0xf64 0xf67 0xf6a 0xf6d 0xf70 0xf73 0xf76 0xf79 0xf7c 0xf7f 0xf82 0xf85 0xf88 0xf8b 0xf8e 0xf91 0xf94 0xf97 0xf9a 0xf9d 0xfa0 0xfa3 0xfa6 0xfa9 0xfac 0xfaf 0xfb2 0xfb5 0xfb8 0xfbb 0xfbe 0xfc1 0xfc4 0xfc7 0xfca 0xfcd 0xfd0 0xfd3 0xfd6 0xfd9 0xfdc 0xfdf 0xfe2 0xfe5 0xfe8 0xfeb 0xff0 0xff5 0xffa 0xfff 0x1004 0x1009 0x100e 0x1013 0x1018 0x101d 0x1022 0x1027 0x102c 0x1031 0x1036 0x103b 0x1040 0x1045 0x104a 0x104f 0x1054 0x1059 0x105e 0x1068>;
		};

		key0 {
			compatible = "rockchip,key";
			io-channels = <0xba 0x00>;
			adc-drift = <0x2d>;

			home-key {
				sr,code = <0x01>;
				label = "home";
				rockchip,adc_value = <0xea>;
			};

			stop-key {
				sr,code = <0x02>;
				label = "stop";
				rockchip,adc_value = <0x01>;
			};

			return-key {
				sr,code = <0x03>;
				label = "return";
				rockchip,adc_value = <0x6b>;
			};

			snapshot-key {
				sr,code = <0x04>;
				label = "snapshot";
				rockchip,adc_value = <0x15c>;
			};

			recording-key {
				sr,code = <0x05>;
				label = "recording";
				rockchip,adc_value = <0x1ca>;
			};

			cus1-key {
				sr,code = <0x06>;
				label = "customer1";
				gpios = <0x9c 0x01 0x01>;
			};

			cus2-key {
				sr,code = <0x07>;
				label = "customer2";
				gpios = <0x9c 0x00 0x01>;
			};

			cus3-key {
				sr,code = <0x08>;
				label = "customer3";
				gpios = <0xbb 0x1f 0x01>;
			};

			joybtn-key {
				sr,code = <0x09>;
				label = "joystick_btn";
				gpios = <0x9c 0x02 0x01>;
			};

			gimbala-key {
				sr,code = <0x0a>;
				label = "gimbal_A";
				gpios = <0x9c 0x04 0x01>;
			};

			gimbalb-key {
				sr,code = <0x0b>;
				label = "gimbal_B";
				gpios = <0x9c 0x03 0x01>;
			};
		};
	};

	pwm@20040000 {
		compatible = "rockchip,rk-pwm";
		reg = <0x20040000 0x10>;
		interrupts = <0x00 0x27 0x04>;
		#pwm-cells = <0x02>;
		pinctrl-names = "default";
		pinctrl-0 = <0xbc>;
		clocks = <0xbd 0x0f 0x79 0x06>;
		clock-names = "pwm\0pclk";
		status = "okay";
		linux,phandle = <0xed>;
		phandle = <0xed>;
	};

	pwm@20040010 {
		compatible = "rockchip,rk-pwm";
		reg = <0x20040010 0x10>;
		interrupts = <0x00 0x27 0x04>;
		#pwm-cells = <0x02>;
		pinctrl-names = "default";
		pinctrl-0 = <0xbe>;
		clocks = <0xbd 0x0f 0x79 0x06>;
		clock-names = "pwm\0pclk";
		status = "disabled";
	};

	pwm@20040020 {
		compatible = "rockchip,rk-pwm";
		reg = <0x20040020 0x10>;
		interrupts = <0x00 0x27 0x04>;
		#pwm-cells = <0x02>;
		pinctrl-names = "default";
		pinctrl-0 = <0xbf>;
		clocks = <0xbd 0x0f 0x79 0x06>;
		clock-names = "pwm\0pclk";
		status = "disabled";
	};

	pwm@20040030 {
		compatible = "rockchip,rk-pwm";
		reg = <0x20040030 0x10>;
		interrupts = <0x00 0x27 0x04>;
		#pwm-cells = <0x02>;
		pinctrl-names = "default";
		pinctrl-0 = <0xc0>;
		clocks = <0xbd 0x0f 0x79 0x06>;
		clock-names = "pwm\0pclk";
		status = "okay";
		linux,phandle = <0xee>;
		phandle = <0xee>;
	};

	syscon@20200000 {
		compatible = "rockchip,rv1108-cru\0rockchip,cru\0syscon";
		reg = <0x20200000 0x1000>;
	};

	reset@20200180 {
		compatible = "rockchip,reset";
		reg = <0x20200180 0x30>;
		rockchip,reset-flag = <0x01>;
		#reset-cells = <0x01>;
		linux,phandle = <0xc1>;
		phandle = <0xc1>;
	};

	codec@20230000 {
		compatible = "rockchip,rv1108-codec";
		reg = <0x20230000 0x1000>;
		rockchip,grf = <0x99>;
		clocks = <0x7b 0x06>;
		clock-names = "g_pclk_acodec";
		spk_ctl_io = <0x9b 0x08 0x00>;
		status = "okay";
		linux,phandle = <0xf1>;
		phandle = <0xf1>;
	};

	rkvenc_srv {
		compatible = "rockchip,mpp_service";
		linux,phandle = <0xc2>;
		phandle = <0xc2>;
	};

	rkvenc@28000000 {
		compatible = "rockchip,rv1108-rkvenc\0rockchip,rkvenc";
		rockchip,grf = <0x99>;
		iommu_enabled = <0x00>;
		reg = <0x28000000 0x8ec>;
		interrupts = <0x00 0x08 0x04>;
		clocks = <0x04 0x7e 0x09 0x4c>;
		clock-names = "aclk_vcodec\0hclk_vcodec\0clk_core";
		resets = <0xc1 0xad 0xc1 0xac 0xc1 0xae>;
		reset-names = "video_h\0video_a\0video_c";
		rockchip,srv = <0xc2>;
		status = "okay";
	};

	vpu_service@30000000 {
		compatible = "rockchip,rv1108-vpu\0vpu_service";
		rockchip,grf = <0x99>;
		iommu_enabled = <0x00>;
		reg = <0x30000000 0x800>;
		interrupts = <0x00 0x09 0x04 0x00 0x0a 0x04>;
		interrupt-names = "irq_dec\0irq_enc";
		clocks = <0x4b 0x7e 0x03>;
		clock-names = "aclk_vcodec\0hclk_vcodec";
		resets = <0xc1 0xa3 0xc1 0xa2>;
		reset-names = "video_h\0video_a";
		dev_mode = <0x00>;
		status = "okay";
	};

	rkvdec@30010000 {
		compatible = "rockchip,rv1108-rkvdec\0rockchip,rkvdec";
		rockchip,grf = <0x99>;
		iommu_enabled = <0x00>;
		reg = <0x30010000 0x400>;
		interrupts = <0x00 0x07 0x04>;
		interrupt-names = "irq_dec";
		clocks = <0x49 0x7e 0x02 0x4a 0x05>;
		clock-names = "aclk_vcodec\0hclk_vcodec\0clk_cabac\0clk_core";
		resets = <0xc1 0xa7 0xc1 0xa6>;
		reset-names = "video_h\0video_a";
		dev_mode = <0x02>;
		status = "okay";
	};

	fb {
		status = "okay";
		compatible = "rockchip,rk-fb";
		rockchip,disp-mode = <0x00>;
		rockchip,uboot-logo-on = <0x00>;
	};

	rk_screen {
		status = "okay";
		compatible = "rockchip,screen";

		screen_init {
			screen-init-type = <0x02>;
			cs-gpio = <0x9c 0x11 0x01>;
			rst-gpio = <0x9b 0x13 0x01>;
			scl-gpio = <0x9c 0x0f 0x01>;
			sdi-gpio = <0x9c 0x10 0x01>;
			lcd_enable = <0x9b 0x05 0x01>;
		};
	};

	cif_isp@30020000 {
		compatible = "rockchip,rv1108-cif-isp";
		rockchip,grf = <0x99>;
		reg = <0x30020000 0x10000 0x20258000 0x8000 0x20200000 0x1000>;
		reg-names = "register\0csiphy_base\0cru_base";
		clocks = <0xc3 0x0c 0xc3 0x0b 0x38 0x38 0x7b 0x0c 0xc3 0x0a 0xc4 0x0c>;
		clock-names = "aclk_isp\0hclk_isp\0sclk_isp\0sclk_isp_jpe\0pclk_mipi_csi\0pclk_isp_in\0sclk_mipidsi_24m";
		resets = <0xc1 0x83 0xc1 0x80 0xc1 0x81 0xc1 0x82>;
		reset-names = "rst_isp\0rst_isp_niu_a\0rst_isp_niu_h\0rst_isp_h";
		interrupts = <0x00 0x39 0x04>;
		interrupt-names = "cif_isp11_irq";
		status = "disabled";
		rockchip,camera-modules-attached = <0xc5 0xc6 0xc7 0xc8>;
	};

	iep@30030000 {
		compatible = "rockchip,iep";
		iommu_enabled = <0x00>;
		reg = <0x30030000 0x800>;
		interrupts = <0x00 0x1b 0x04>;
		clocks = <0xc3 0x02 0xc3 0x03>;
		clock-names = "aclk_iep\0hclk_iep";
		version = <0x03>;
		status = "okay";
	};

	vop@30040000 {
		status = "okay";
		compatible = "rockchip,rv1108-lcdc-lite";
		rockchip,grf = <0x99>;
		rockchip,prop = <0x01>;
		rockchip,pwr18 = <0x00>;
		rockchip,iommu-enabled = <0x00>;
		reg = <0x30040000 0xe00 0x20228000 0x400 0x300e0000 0x400>;
		reg-names = "vop_reg\0mipi_dsi_phy\0mipi_dsi_host";
		interrupts = <0x00 0x1c 0x04>;
		clocks = <0xc3 0x00 0x55 0xc3 0x01>;
		clock-names = "aclk_lcdc\0dclk_lcdc\0hclk_lcdc";
		pinctrl-names = "default\0gpio";
		pinctrl-0 = <0xc9>;
		pinctrl-1 = <0xca>;

		power_ctr {
			rockchip,debug = <0x00>;
		};
	};

	tve@30040e00 {
		compatible = "rockchip,rv1108-tve";
		reg = <0x30040e00 0x100 0x20250000 0x10000>;
		clocks = <0x7b 0x09>;
		clock-names = "pclk_vdac";
		saturation = <0x325d46>;
		brightcontrast = <0x9e00>;
		adjtiming = <0xc6c00880>;
		lumafilter0 = <0x2ff0000>;
		lumafilter1 = <0xf40200fe>;
		lumafilter2 = <0xf332d910>;
		daclevel = <0x2f>;
		dac1level = <0x0f>;
		status = "okay";
	};

	rga@30050000 {
		compatible = "rockchip,rga2";
		reg = <0x30050000 0x1000>;
		interrupts = <0x00 0x1d 0x04>;
		clocks = <0xc3 0x04 0xc3 0x05 0x45>;
		clock-names = "aclk_rga\0hclk_rga\0clk_rga";
		status = "okay";
	};

	cif1to4 {
		compatible = "rockchip,rv1108-cif1to4\0rockchip,cif1to4";
		rockchip,grf = <0x99>;
		clocks = <0x74 0x08 0x39 0x40>;
		clock-names = "cif1to4_pclk\0pclkin_vip\0pclkin_vip_inv";
		resets = <0xc1 0x90>;
		reset-names = "cif1to4_rst";
		status = "disabled";
	};

	cif_cif@30060000 {
		compatible = "rockchip,rv1108-cif-cif";
		rockchip,grf = <0x99>;
		reg = <0x30060000 0x10000>;
		clocks = <0xc3 0x06 0xc3 0x07 0x74 0x09 0x61 0x3b 0x39 0x3a 0x3f 0x40>;
		clock-names = "aclk_cif\0hclk_cif\0pclkin_cif\0vip_clk\0pclkin_cvbs2cif\0pclkin_vip\0pclk_cif1t4_out\0pclkin_vip_ninv\0pclkin_vip_inv";
		resets = <0xc1 0x84 0xc1 0x85 0xc1 0x86>;
		reset-names = "cif_arst\0cif_hrst\0cif_prst";
		interrupts = <0x00 0x36 0x04>;
		status = "disabled";
		rockchip,camera-modules-attached = <0xcb 0xcc>;
	};

	cvbsin@30070000 {
		compatible = "rockchip,rv1108-cvbsin\0rockchip,cvbsin";
		rockchip,grf = <0x99>;
		reg = <0x30070000 0x10000>;
		device_type = "v4l2-pltfrm-subdev";
		clocks = <0x46 0x08 0xcd 0x07 0xce 0x0c>;
		clock-names = "clk_cvbs\0clk_cvbs_parent\0pclk_cvbs\0hclk_cvbs";
		resets = <0xc1 0x7c 0xc1 0x91 0xc1 0x92>;
		reset-names = "cvbs_prst\0cvbs_clk_rst\0cvbs_hrst";
		status = "okay";
		linux,phandle = <0xcc>;
		phandle = <0xcc>;
	};

	cif_cif@30080000 {
		compatible = "rockchip,rv1108-cif-cif";
		rockchip,grf = <0x99>;
		reg = <0x30080000 0x10000>;
		clocks = <0xce 0x06 0xce 0x07 0x74 0x0a 0x62 0x3b 0x39 0x3c>;
		clock-names = "aclk_cif\0hclk_cif\0pclkin_cif\0vip_clk\0pclkin_cvbs2cif\0pclkin_vip\0pclk_cif1t4_out";
		resets = <0xc1 0x87 0xc1 0x88 0xc1 0x89>;
		reset-names = "cif_arst\0cif_hrst\0cif_prst";
		interrupts = <0x00 0x3a 0x04>;
		status = "disabled";
		rockchip,camera-modules-attached = <0xcb>;
	};

	cif_cif@30090000 {
		compatible = "rockchip,rv1108-cif-cif";
		rockchip,grf = <0x99>;
		reg = <0x30090000 0x10000>;
		clocks = <0xce 0x08 0xce 0x09 0x74 0x0b 0x63 0x3b 0x39 0x3d>;
		clock-names = "aclk_cif\0hclk_cif\0pclkin_cif\0vip_clk\0pclkin_cvbs2cif\0pclkin_vip\0pclk_cif1t4_out";
		resets = <0xc1 0x8a 0xc1 0x8b 0xc1 0x8c>;
		reset-names = "cif_arst\0cif_hrst\0cif_prst";
		interrupts = <0x00 0x3b 0x04>;
		status = "disabled";
		rockchip,camera-modules-attached = <0xcb>;
	};

	cif_cif@300a0000 {
		compatible = "rockchip,rv1108-cif-cif";
		rockchip,grf = <0x99>;
		reg = <0x300a0000 0x10000>;
		clocks = <0xce 0x0a 0xce 0x0b 0x74 0x0c 0x64 0x3b 0x39 0x3e>;
		clock-names = "aclk_cif\0hclk_cif\0pclkin_cif\0vip_clk\0pclkin_cvbs2cif\0pclkin_vip\0pclk_cif1t4_out";
		resets = <0xc1 0x8d 0xc1 0x8e 0xc1 0x8f>;
		reset-names = "cif_arst\0cif_hrst\0cif_prst";
		interrupts = <0x00 0x3c 0x04>;
		status = "disabled";
		rockchip,camera-modules-attached = <0xcb>;
	};

	mipi_dsi@300e0000 {
		compatible = "rockchip,rv1108-dsi";
		rockchip,prop = <0x00>;
		reg = <0x300e0000 0x10000 0x20228000 0x8000>;
		reg-names = "mipi_dsi_host\0mipi_dsi_phy";
		interrupts = <0x00 0x37 0x04>;
		clocks = <0xc4 0x0a 0x7b 0x0b 0xc3 0x08>;
		clock-names = "clk_mipi_24m\0pclk_mipi_dsi\0pclk_mipi_dsi_host";
		status = "disabled";
	};

	hdmi@300c0000 {
		compatible = "rockchip,rv1108-hdmi";
		reg = <0x300c0000 0x20000 0x20220000 0x8000>;
		interrupts = <0x00 0x15 0x04 0x00 0x16 0x04 0x00 0x06 0x04>;
		clocks = <0xcd 0x08 0xc3 0x09 0x7b 0x08 0x48 0xcf>;
		clock-names = "hdcp_clk_hdmi\0pclk_hdmi\0pclk_hdmi_phy\0cec_clk_hdmi\0dclk_hdmi_phy";
		pinctrl-names = "default\0gpio";
		pinctrl-0 = <0xd0 0xae 0xd1>;
		pinctrl-1 = <0xd2>;
		resets = <0xc1 0x7d>;
		reset-names = "hdmi";
		rockchip,grf = <0x99>;
		rockchip,hdmi_audio_source = <0x00>;
		rockchip,hdcp_enable = <0x00>;
		rockchip,cec_enable = <0x00>;
		rockchip,phy_table = <0x5f5e100 0x00 0x00 0x05 0x08 0x08 0x08 0x9d5b340 0x08 0x0d 0x05 0x08 0x08 0x08>;
		status = "disabled";
	};

	nandc@30100000 {
		compatible = "rockchip,nandc";
		reg = <0x30100000 0x1000>;
		interrupts = <0x00 0x0e 0x04>;
		clocks = <0x34 0x7c 0x03 0xd3 0x03>;
		clock-names = "clk_nandc\0hclk_nandc\0g_clk_nandc";
		status = "okay";
	};

	rksdmmc@30110000 {
		compatible = "rockchip,rk_mmc\0rockchip,rv1108-sdmmc";
		reg = <0x30110000 0x10000>;
		interrupts = <0x00 0x0d 0x04>;
		#address-cells = <0x01>;
		#size-cells = <0x00>;
		clocks = <0x32 0x7c 0x02>;
		clock-names = "clk_mmc\0hclk_mmc";
		num-slots = <0x01>;
		fifo-depth = <0x100>;
		bus-width = <0x08>;
		tune_regsbase = <0x1e8>;
		resets = <0xc1 0x56>;
		reset-names = "mmc_ahb_reset";
		status = "disabled";
		clock-frequency = <0x2faf080>;
		clock-freq-min-max = <0x61a80 0x2faf080>;
		supports-highspeed;
		supports-emmc;
		bootpart-no-access;
		supports-DDR_MODE;
		caps2-mmc-hs200;
		ignore-pm-notify;
		keep-power-in-suspend;
	};

	rksdmmc@30120000 {
		compatible = "rockchip,rk_mmc\0rockchip,rv1108-sdmmc";
		reg = <0x30120000 0x10000>;
		interrupts = <0x00 0x0c 0x04>;
		#address-cells = <0x01>;
		#size-cells = <0x00>;
		pinctrl-names = "default\0idle";
		pinctrl-0 = <0xd4 0xd5 0xd6>;
		pinctrl-1 = <0xd7>;
		clocks = <0x31 0x7c 0x01>;
		clock-names = "clk_mmc\0hclk_mmc";
		num-slots = <0x01>;
		fifo-depth = <0x100>;
		bus-width = <0x04>;
		tune_regsbase = <0x1e0>;
		resets = <0xc1 0x55>;
		reset-names = "mmc_ahb_reset";
		status = "okay";
		clock-frequency = <0x2faf080>;
		clock-freq-min-max = <0x30d40 0x2faf080>;
		supports-highspeed;
		supports-sdio;
		ignore-pm-notify;
		keep-power-in-suspend;
		cap-sdio-irq;
	};

	rksdmmc@30130000 {
		compatible = "rockchip,rk_mmc\0rockchip,rv1108-sdmmc";
		reg = <0x30130000 0x10000>;
		interrupts = <0x00 0x0b 0x04>;
		#address-cells = <0x01>;
		#size-cells = <0x00>;
		pinctrl-names = "default\0idle";
		pinctrl-0 = <0xd8 0xd9 0xda 0xdb 0xdc>;
		pinctrl-1 = <0xdd 0xda 0xdc>;
		cd-gpios = <0x9b 0x01 0x00>;
		clocks = <0x30 0x7c 0x00>;
		clock-names = "clk_mmc\0hclk_mmc";
		num-slots = <0x01>;
		fifo-depth = <0x100>;
		bus-width = <0x04>;
		tune_regsbase = <0x1d8>;
		resets = <0xc1 0x54>;
		reset-names = "mmc_ahb_reset";
		status = "okay";
		clock-frequency = <0x2faf080>;
		clock-freq-min-max = <0x30d40 0x2faf080>;
		supports-highspeed;
		supports-sd;
		broken-cd;
		card-detect-delay = <0xc8>;
		ignore-pm-notify;
		keep-power-in-suspend;
		power-inverted;
	};

	dwc-control-usb {
		compatible = "rockchip,rv1108-dwc-control-usb";
		rockchip,grf = <0x99>;
		rockchip,usbgrf = <0xde>;
		interrupts = <0x00 0x30 0x04>;
		interrupt-names = "otg-irq";
		clocks = <0x7c 0x08 0x7c 0x09>;
		clock-names = "hclk_otg\0hclk_otg_pmu";
		status = "okay";
		vbus_drv = <0x9c 0x15 0x01>;
		rockchip,remote_wakeup;
		rockchip,usb_irq_wakeup;

		usb_bc {
			compatible = "inno,phy";
			regbase = "/dwc-control-usb";
			rk_usb,bvalid = <0x480 0x0a 0x01>;
			rk_usb,iddig = <0x480 0x0d 0x01>;
			rk_usb,vdmsrcen = <0x108 0x0c 0x01>;
			rk_usb,vdpsrcen = <0x108 0x0b 0x01>;
			rk_usb,rdmpden = <0x108 0x0a 0x01>;
			rk_usb,idpsrcen = <0x108 0x09 0x01>;
			rk_usb,idmsinken = <0x108 0x08 0x01>;
			rk_usb,idpsinken = <0x108 0x07 0x01>;
			rk_usb,dpattach = <0x804 0x02 0x01>;
			rk_usb,cpdet = <0x804 0x01 0x01>;
			rk_usb,dcpattach = <0x804 0x00 0x01>;
		};
	};

	usb2-phy {
		compatible = "rockchip,rv1108-usb2phy";
		rockchip,grf = <0x99>;
		rockchip,usbgrf = <0xde>;
		interrupts = <0x00 0x33 0x04>;
		interrupt-names = "linestate";
		#phy-cells = <0x00>;
		status = "disabled";
	};

	usb@30140000 {
		compatible = "generic-ehci";
		reg = <0x30140000 0x20000>;
		interrupts = <0x00 0x0f 0x04>;
		clocks = <0x7c 0x06 0x7c 0x07>;
		clock-names = "hclk_host0\0hclk_host0_arb";
		status = "okay";
	};

	usb@30160000 {
		compatible = "generic-ohci";
		reg = <0x30160000 0x20000>;
		interrupts = <0x00 0x10 0x04>;
		clocks = <0x7c 0x06 0x7c 0x07>;
		clock-names = "hclk_host0\0hclk_host0_arb";
		status = "okay";
	};

	usb@30180000 {
		compatible = "rockchip,rv1108_usb20_otg";
		reg = <0x30180000 0x40000>;
		interrupts = <0x00 0x12 0x04>;
		rockchip,usb-mode = <0x00>;
		rockchip,usb-early-detect = <0x03>;
		status = "okay";
		rockchip,delay-en-diepint-nak-quirk;
		rockchip,high-bandwidth;
	};

	sfc@301c0000 {
		compatible = "rockchip,sfc";
		reg = <0x301c0000 0x200>;
		interrupts = <0x00 0x38 0x04>;
		clocks = <0x33 0x7c 0x0a>;
		clock-names = "clk_sfc\0hclk_sfc";
		status = "okay";
	};

	eth@30200000 {
		compatible = "rockchip,rv1108-gmac";
		reg = <0x30200000 0x10000>;
		rockchip,grf = <0x99>;
		interrupts = <0x00 0x13 0x04>;
		interrupt-names = "macirq";
		clocks = <0x60 0xdf 0x08 0xdf 0x08 0xdf 0x06 0xdf 0x07 0x7c 0x04 0x7c 0x05>;
		clock-names = "clk_mac\0mac_clk_rx\0mac_clk_tx\0clk_mac_ref\0clk_mac_refout\0aclk_mac\0pclk_mac";
		phy-mode = "rmii";
		pinctrl-names = "default";
		pinctrl-0 = <0xe0>;
		status = "disabled";
		reset-gpio = <0xac 0x11 0x01>;
		clock_in_out = "output";
	};

	interrupt-controller@32010000 {
		compatible = "arm,cortex-a15-gic";
		interrupt-controller;
		#interrupt-cells = <0x03>;
		#address-cells = <0x00>;
		reg = <0x32011000 0x1000 0x32012000 0x1000>;
		linux,phandle = <0x02>;
		phandle = <0x02>;
	};

	dsp@33000000 {
		compatible = "rockchip,rv1108-dsp\0rockchip,dsp";
		reg = <0x33800000 0x10000 0x33000000 0x800000 0x33810000 0x10000>;
		clocks = <0x51 0x7d 0x0d 0x66 0x67 0x68 0x69>;
		clock-names = "clk_dsp\0clk_dsp_free\0clk_dsp_iop\0clk_dsp_epp\0clk_dsp_edp\0clk_dsp_edap";
		resets = <0xc1 0xb0 0xc1 0xb1 0xc1 0xb2 0xc1 0xb3>;
		reset-names = "core_rst\0sys_rst\0global_rst\0oecm_rst";
		interrupts = <0x00 0x3d 0x04>;
		rockchip,dsp-timeout-ms = <0x3e8>;
		rockchip,dsp-idle-ms = <0x32>;
		rockchip,dsp-heap-size = <0x00>;
		rockchip,dsp-reload-firmware = <0x00>;
	};

	pinctrl {
		compatible = "rockchip,rv1108-pinctrl";
		rockchip,grf = <0x99>;
		rockchip,pmugrf = <0xe1>;
		#address-cells = <0x01>;
		#size-cells = <0x01>;
		ranges;

		gpio0@20030000 {
			compatible = "rockchip,gpio-bank";
			reg = <0x20030000 0x100>;
			interrupts = <0x00 0x28 0x04>;
			clocks = <0x79 0x02>;
			gpio-controller;
			#gpio-cells = <0x02>;
			interrupt-controller;
			#interrupt-cells = <0x02>;
			linux,phandle = <0x9b>;
			phandle = <0x9b>;
		};

		gpio1@10310000 {
			compatible = "rockchip,gpio-bank";
			reg = <0x10310000 0x100>;
			interrupts = <0x00 0x29 0x04>;
			clocks = <0x7a 0x07>;
			gpio-controller;
			#gpio-cells = <0x02>;
			interrupt-controller;
			#interrupt-cells = <0x02>;
			linux,phandle = <0xac>;
			phandle = <0xac>;
		};

		gpio2@10320000 {
			compatible = "rockchip,gpio-bank";
			reg = <0x10320000 0x100>;
			interrupts = <0x00 0x2a 0x04>;
			clocks = <0x7a 0x08>;
			gpio-controller;
			#gpio-cells = <0x02>;
			interrupt-controller;
			#interrupt-cells = <0x02>;
			linux,phandle = <0xbb>;
			phandle = <0xbb>;
		};

		gpio3@10330000 {
			compatible = "rockchip,gpio-bank";
			reg = <0x10330000 0x100>;
			interrupts = <0x00 0x2b 0x04>;
			clocks = <0x7a 0x09>;
			gpio-controller;
			#gpio-cells = <0x02>;
			interrupt-controller;
			#interrupt-cells = <0x02>;
			linux,phandle = <0x9c>;
			phandle = <0x9c>;
		};

		pcfg-pull-up {
			bias-pull-up;
			linux,phandle = <0xe4>;
			phandle = <0xe4>;
		};

		pcfg-pull-down {
			bias-pull-down;
			linux,phandle = <0xe8>;
			phandle = <0xe8>;
		};

		pcfg-pull-none {
			bias-disable;
			linux,phandle = <0xe3>;
			phandle = <0xe3>;
		};

		pcfg-pull-none-drv-8ma {
			drive-strength = <0x08>;
			linux,phandle = <0xe6>;
			phandle = <0xe6>;
		};

		pcfg-pull-none-drv-12ma {
			drive-strength = <0x0c>;
			linux,phandle = <0xeb>;
			phandle = <0xeb>;
		};

		pcfg-pull-up-drv-8ma {
			bias-pull-up;
			drive-strength = <0x08>;
			linux,phandle = <0xe7>;
			phandle = <0xe7>;
		};

		pcfg-pull-none-drv-4ma {
			drive-strength = <0x04>;
			linux,phandle = <0xea>;
			phandle = <0xea>;
		};

		pcfg-pull-up-drv-4ma {
			bias-pull-up;
			drive-strength = <0x04>;
			linux,phandle = <0xe9>;
			phandle = <0xe9>;
		};

		pcfg-pull-none-smt {
			bias-disable;
			input-schmitt-enable;
			linux,phandle = <0xe2>;
			phandle = <0xe2>;
		};

		pcfg-output-high {
			output-high;
		};

		pcfg-output-low {
			output-low;
		};

		pcfg-input-high {
			bias-pull-up;
			input-enable;
			linux,phandle = <0xe5>;
			phandle = <0xe5>;
		};

		i2c0 {

			i2c0-xfer {
				rockchip,pins = <0x00 0x09 0x01 0xe2 0x00 0x0a 0x01 0xe2>;
				linux,phandle = <0x9a>;
				phandle = <0x9a>;
			};
		};

		i2c1 {

			i2c1-xfer {
				rockchip,pins = <0x02 0x1b 0x01 0xe2 0x02 0x1c 0x01 0xe2>;
				linux,phandle = <0xa1>;
				phandle = <0xa1>;
			};
		};

		i2c2m1 {

			i2c2m1-xfer {
				rockchip,pins = <0x00 0x12 0x02 0xe2 0x00 0x16 0x03 0xe2>;
				linux,phandle = <0xae>;
				phandle = <0xae>;
			};

			i2c2m1-gpio {
				rockchip,pins = <0x00 0x12 0x00 0xe3 0x00 0x16 0x00 0xe3>;
				linux,phandle = <0xd2>;
				phandle = <0xd2>;
			};
		};

		i2c2m05v {

			i2c2m05v-xfer {
				rockchip,pins = <0x01 0x1d 0x02 0xe2 0x01 0x1c 0x02 0xe2>;
			};

			i2c2m05v-gpio {
				rockchip,pins = <0x01 0x1d 0x00 0xe3 0x01 0x1c 0x00 0xe3>;
			};
		};

		i2c3 {

			i2c3-xfer {
				rockchip,pins = <0x00 0x0e 0x01 0xe2 0x00 0x14 0x02 0xe2>;
				linux,phandle = <0xaf>;
				phandle = <0xaf>;
			};
		};

		uart0 {

			uart0-xfer {
				rockchip,pins = <0x03 0x06 0x01 0xe4 0x03 0x05 0x01 0xe3>;
				linux,phandle = <0x97>;
				phandle = <0x97>;
			};

			uart0-cts {
				rockchip,pins = <0x03 0x04 0x01 0xe3>;
			};

			uart0-rts {
				rockchip,pins = <0x03 0x03 0x01 0xe3>;
			};

			uart0-rts-gpio {
				rockchip,pins = <0x03 0x03 0x00 0xe3>;
			};
		};

		uart1 {

			uart1-xfer {
				rockchip,pins = <0x01 0x1b 0x01 0xe4 0x01 0x1a 0x01 0xe3>;
				linux,phandle = <0x93>;
				phandle = <0x93>;
			};

			uart1-cts {
				rockchip,pins = <0x01 0x18 0x01 0xe3>;
				linux,phandle = <0x94>;
				phandle = <0x94>;
			};

			uart1-rts {
				rockchip,pins = <0x01 0x19 0x01 0xe3>;
				linux,phandle = <0x95>;
				phandle = <0x95>;
			};
		};

		uart2m0 {

			uart2m0-xfer {
				rockchip,pins = <0x02 0x1a 0x01 0xe4 0x02 0x19 0x01 0xe3>;
				linux,phandle = <0x98>;
				phandle = <0x98>;
			};
		};

		uart2m1 {

			uart2m1-xfer {
				rockchip,pins = <0x03 0x13 0x02 0xe4 0x03 0x12 0x02 0xe3>;
				linux,phandle = <0x91>;
				phandle = <0x91>;
			};
		};

		uart2_5v {

			uart2_5v-cts {
				rockchip,pins = <0x01 0x1c 0x01 0xe3>;
			};

			uart2_5v-rts {
				rockchip,pins = <0x01 0x1d 0x01 0xe3>;
			};
		};

		spim0 {

			spim0-clk {
				rockchip,pins = <0x01 0x18 0x02 0xe4>;
				linux,phandle = <0xb0>;
				phandle = <0xb0>;
			};

			spim0-cs0 {
				rockchip,pins = <0x01 0x19 0x02 0xe4>;
				linux,phandle = <0xb3>;
				phandle = <0xb3>;
			};

			spim0-tx {
				rockchip,pins = <0x01 0x1b 0x02 0xe4>;
				linux,phandle = <0xb1>;
				phandle = <0xb1>;
			};

			spim0-rx {
				rockchip,pins = <0x01 0x1a 0x02 0xe4>;
				linux,phandle = <0xb2>;
				phandle = <0xb2>;
			};
		};

		spim1 {

			spim1-clk {
				rockchip,pins = <0x00 0x03 0x01 0xe4>;
			};

			spim1-cs0 {
				rockchip,pins = <0x00 0x04 0x01 0xe4>;
			};

			spim1-rx {
				rockchip,pins = <0x00 0x08 0x01 0xe4>;
			};

			spim1-tx {
				rockchip,pins = <0x00 0x07 0x01 0xe4>;
			};
		};

		i2sm0 {

			i2sm0-mclk {
				rockchip,pins = <0x01 0x0c 0x02 0xe3>;
				linux,phandle = <0x81>;
				phandle = <0x81>;
			};

			i2sm0-sclk {
				rockchip,pins = <0x01 0x0b 0x02 0xe3>;
				linux,phandle = <0x82>;
				phandle = <0x82>;
			};

			i2sm0-lrckrx {
				rockchip,pins = <0x01 0x10 0x02 0xe3>;
				linux,phandle = <0x83>;
				phandle = <0x83>;
			};

			i2sm0-lrcktx {
				rockchip,pins = <0x01 0x0e 0x02 0xe3>;
				linux,phandle = <0x84>;
				phandle = <0x84>;
			};

			i2sm0-sdi {
				rockchip,pins = <0x01 0x11 0x02 0xe3>;
				linux,phandle = <0x85>;
				phandle = <0x85>;
			};

			i2sm0-sdo0 {
				rockchip,pins = <0x01 0x0a 0x02 0xe3>;
				linux,phandle = <0x86>;
				phandle = <0x86>;
			};

			i2sm0-sdo1 {
				rockchip,pins = <0x01 0x0d 0x02 0xe3>;
				linux,phandle = <0x87>;
				phandle = <0x87>;
			};

			i2sm0-sdo2 {
				rockchip,pins = <0x01 0x0f 0x02 0xe3>;
				linux,phandle = <0x88>;
				phandle = <0x88>;
			};

			i2sm0-sdo3 {
				rockchip,pins = <0x01 0x12 0x02 0xe3>;
				linux,phandle = <0x89>;
				phandle = <0x89>;
			};

			i2sm0-gpio {
				rockchip,pins = <0x01 0x0c 0x00 0xe5 0x01 0x0b 0x00 0xe5 0x01 0x10 0x00 0xe5 0x01 0x0e 0x00 0xe5 0x01 0x11 0x00 0xe5 0x01 0x0a 0x00 0xe5 0x01 0x0d 0x00 0xe5 0x01 0x0f 0x00 0xe5 0x01 0x12 0x00 0xe5>;
				linux,phandle = <0x8a>;
				phandle = <0x8a>;
			};
		};

		i2sm1 {

			i2sm1-mclk {
				rockchip,pins = <0x02 0x15 0x02 0xe3>;
			};

			i2sm1-sclk {
				rockchip,pins = <0x02 0x14 0x02 0xe3>;
			};

			i2sm1-lrckrx {
				rockchip,pins = <0x02 0x10 0x02 0xe3>;
			};

			i2sm1-lrcktx {
				rockchip,pins = <0x01 0x16 0x02 0xe3>;
			};

			i2sm1-sdi {
				rockchip,pins = <0x02 0x11 0x02 0xe3>;
			};

			i2sm1-sdo0 {
				rockchip,pins = <0x02 0x13 0x02 0xe3>;
			};

			i2sm1-sdo1 {
				rockchip,pins = <0x02 0x16 0x02 0xe3>;
			};

			i2sm1-sdo2 {
				rockchip,pins = <0x01 0x17 0x02 0xe3>;
			};

			i2sm1-sdo3 {
				rockchip,pins = <0x03 0x1b 0x02 0xe3>;
			};

			i2sm1-gpio {
				rockchip,pins = <0x02 0x15 0x00 0xe5 0x02 0x14 0x00 0xe5 0x02 0x10 0x00 0xe5 0x01 0x16 0x00 0xe5 0x02 0x11 0x00 0xe5 0x02 0x13 0x00 0xe5 0x02 0x16 0x00 0xe5 0x01 0x17 0x00 0xe5 0x03 0x1b 0x00 0xe5>;
			};
		};

		pcm {

			pcm-tx {
				rockchip,pins = <0x03 0x09 0x01 0xe3>;
				linux,phandle = <0x8b>;
				phandle = <0x8b>;
			};

			pcm-rx {
				rockchip,pins = <0x03 0x0a 0x01 0xe3>;
				linux,phandle = <0x8c>;
				phandle = <0x8c>;
			};

			pcm-clk {
				rockchip,pins = <0x03 0x0b 0x01 0xe3>;
				linux,phandle = <0x8e>;
				phandle = <0x8e>;
			};

			pcm-sync {
				rockchip,pins = <0x03 0x0c 0x01 0xe3>;
				linux,phandle = <0x8d>;
				phandle = <0x8d>;
			};

			pcm-sleep {
				rockchip,pins = <0x03 0x09 0x00 0xe5 0x03 0x0a 0x00 0xe5 0x03 0x0b 0x00 0xe5 0x03 0x0c 0x00 0xe5>;
				linux,phandle = <0x8f>;
				phandle = <0x8f>;
			};
		};

		emmc {

			emmc-clk {
				rockchip,pins = <0x02 0x0e 0x01 0xe6>;
			};

			emmc-cmd {
				rockchip,pins = <0x02 0x0c 0x02 0xe7>;
			};

			emmc-pwren {
				rockchip,pins = <0x02 0x12 0x02 0xe3>;
			};

			emmc-bus1 {
				rockchip,pins = <0x02 0x00 0x02 0xe7>;
			};

			emmc-bus8 {
				rockchip,pins = <0x02 0x00 0x02 0xe7 0x02 0x01 0x02 0xe7 0x02 0x02 0x02 0xe7 0x02 0x03 0x02 0xe7 0x02 0x04 0x02 0xe7 0x02 0x05 0x02 0xe7 0x02 0x06 0x02 0xe7 0x02 0x07 0x02 0xe7>;
			};
		};

		sdmmc {

			sdmmc-clk {
				rockchip,pins = <0x03 0x14 0x01 0xe6>;
				linux,phandle = <0xd8>;
				phandle = <0xd8>;
			};

			sdmmc-cmd {
				rockchip,pins = <0x03 0x15 0x01 0xe7>;
				linux,phandle = <0xd9>;
				phandle = <0xd9>;
			};

			sdmmc-dectn {
				rockchip,pins = <0x00 0x01 0x01 0xe7>;
				linux,phandle = <0xda>;
				phandle = <0xda>;
			};

			sdmmc-pwren {
				rockchip,pins = <0x03 0x0f 0x01 0xe7>;
				linux,phandle = <0xdc>;
				phandle = <0xdc>;
			};

			sdmmc-bus1 {
				rockchip,pins = <0x03 0x13 0x01 0xe7>;
			};

			sdmmc-bus4 {
				rockchip,pins = <0x03 0x13 0x01 0xe7 0x03 0x12 0x01 0xe7 0x03 0x11 0x01 0xe7 0x03 0x10 0x01 0xe7>;
				linux,phandle = <0xdb>;
				phandle = <0xdb>;
			};

			sdmmc-gpio {
				rockchip,pins = <0x03 0x14 0x00 0xe8 0x03 0x15 0x00 0xe8 0x03 0x13 0x00 0xe8 0x03 0x12 0x00 0xe8 0x03 0x11 0x00 0xe8 0x03 0x10 0x00 0xe8>;
				linux,phandle = <0xdd>;
				phandle = <0xdd>;
			};
		};

		sdio {

			sdio-bus1 {
				rockchip,pins = <0x02 0x1f 0x01 0xe9>;
			};

			sdio-bus4 {
				rockchip,pins = <0x02 0x1f 0x01 0xe9 0x03 0x00 0x01 0xe9 0x03 0x01 0x01 0xe9 0x03 0x02 0x01 0xe9>;
				linux,phandle = <0xd6>;
				phandle = <0xd6>;
			};

			sdio-cmd {
				rockchip,pins = <0x02 0x1e 0x01 0xe9>;
				linux,phandle = <0xd4>;
				phandle = <0xd4>;
			};

			sdio-clk {
				rockchip,pins = <0x02 0x1d 0x01 0xea>;
				linux,phandle = <0xd5>;
				phandle = <0xd5>;
			};

			sdio-pwren {
				rockchip,pins = <0x00 0x02 0x01 0xe4>;
			};

			sdio-gpio {
				rockchip,pins = <0x02 0x1f 0x00 0xe9 0x03 0x00 0x00 0xe9 0x03 0x01 0x00 0xe9 0x03 0x02 0x00 0xe9 0x02 0x1e 0x00 0xe9 0x02 0x1d 0x00 0xe9 0x00 0x02 0x00 0xe9>;
				linux,phandle = <0xd7>;
				phandle = <0xd7>;
			};
		};

		pwm0 {

			pwm0-pin {
				rockchip,pins = <0x00 0x15 0x01 0xe3>;
				linux,phandle = <0xbc>;
				phandle = <0xbc>;
			};
		};

		pwm1 {

			pwm1-pin {
				rockchip,pins = <0x00 0x14 0x01 0xe3>;
				linux,phandle = <0xbe>;
				phandle = <0xbe>;
			};
		};

		pwm2 {

			pwm2-pin {
				rockchip,pins = <0x00 0x16 0x01 0xe3>;
				linux,phandle = <0xbf>;
				phandle = <0xbf>;
			};
		};

		pwm3 {

			pwm3-pin {
				rockchip,pins = <0x00 0x10 0x01 0xe3>;
				linux,phandle = <0xc0>;
				phandle = <0xc0>;
			};
		};

		pwm4 {

			pwm4-pin {
				rockchip,pins = <0x01 0x11 0x03 0xe3>;
				linux,phandle = <0xb4>;
				phandle = <0xb4>;
			};
		};

		pwm5 {

			pwm5-pin {
				rockchip,pins = <0x01 0x07 0x02 0xe3>;
				linux,phandle = <0xb6>;
				phandle = <0xb6>;
			};
		};

		pwm6 {

			pwm6-pin {
				rockchip,pins = <0x01 0x08 0x02 0xe3>;
				linux,phandle = <0xb7>;
				phandle = <0xb7>;
			};
		};

		pwm7 {

			pwm7-pin {
				rockchip,pins = <0x01 0x09 0x02 0xe3>;
				linux,phandle = <0xb8>;
				phandle = <0xb8>;
			};
		};

		gpio1_lcdc0 {

			lcdc-mipi_data {
				rockchip,pins = <0x01 0x00 0x01 0xe3 0x01 0x01 0x01 0xe3 0x01 0x02 0x01 0xe3 0x01 0x03 0x01 0xe3 0x01 0x04 0x01 0xe3 0x01 0x05 0x01 0xe3 0x01 0x06 0x01 0xe3 0x01 0x07 0x01 0xe3 0x01 0x08 0x01 0xe3 0x01 0x09 0x01 0xe3 0x01 0x11 0x01 0xe3 0x01 0x10 0x01 0xe3>;
			};

			lcdc-data {
				rockchip,pins = <0x01 0x15 0x01 0xe3 0x01 0x00 0x01 0xe3 0x01 0x01 0x01 0xe3 0x01 0x02 0x01 0xe3 0x01 0x03 0x01 0xe3 0x01 0x04 0x01 0xe3 0x01 0x05 0x01 0xe3 0x01 0x06 0x01 0xe3 0x01 0x07 0x01 0xe3 0x01 0x08 0x01 0xe3 0x01 0x09 0x01 0xe3 0x01 0x14 0x01 0xe3 0x01 0x13 0x01 0xe3 0x01 0x12 0x01 0xe3 0x01 0x11 0x01 0xe3 0x01 0x10 0x01 0xe3 0x01 0x0f 0x01 0xe3 0x01 0x0e 0x01 0xe3 0x01 0x0d 0x01 0xe3 0x01 0x0c 0x01 0xe3 0x01 0x0b 0x01 0xe3 0x01 0x0a 0x01 0xe3>;
				linux,phandle = <0xc9>;
				phandle = <0xc9>;
			};

			lcdc-mipi_gpio {
				rockchip,pins = <0x01 0x00 0x00 0xe3 0x01 0x01 0x00 0xe3 0x01 0x02 0x00 0xe3 0x01 0x03 0x00 0xe3 0x01 0x04 0x00 0xe3 0x01 0x05 0x00 0xe3 0x01 0x06 0x00 0xe3 0x01 0x07 0x00 0xe3 0x01 0x08 0x00 0xe3 0x01 0x09 0x00 0xe3 0x01 0x11 0x00 0xe3 0x01 0x10 0x00 0xe3>;
			};

			lcdc-gpio {
				rockchip,pins = <0x01 0x15 0x00 0xe3 0x01 0x00 0x00 0xe3 0x01 0x01 0x00 0xe3 0x01 0x02 0x00 0xe3 0x01 0x03 0x00 0xe3 0x01 0x04 0x00 0xe3 0x01 0x05 0x00 0xe3 0x01 0x06 0x00 0xe3 0x01 0x07 0x00 0xe3 0x01 0x08 0x00 0xe3 0x01 0x09 0x00 0xe3 0x01 0x14 0x00 0xe3 0x01 0x13 0x00 0xe3 0x01 0x12 0x00 0xe3 0x01 0x11 0x00 0xe3 0x01 0x10 0x00 0xe3 0x01 0x0f 0x00 0xe3 0x01 0x0e 0x00 0xe3 0x01 0x0d 0x00 0xe3 0x01 0x0c 0x00 0xe3 0x01 0x0b 0x00 0xe3 0x01 0x0a 0x00 0xe3>;
				linux,phandle = <0xca>;
				phandle = <0xca>;
			};
		};

		gmac {

			rmii-pins {
				rockchip,pins = <0x01 0x15 0x02 0xe3 0x01 0x13 0x02 0xe3 0x01 0x14 0x02 0xe3 0x01 0x0a 0x03 0xeb 0x01 0x0b 0x03 0xeb 0x01 0x0c 0x03 0xeb 0x01 0x0d 0x03 0xe3 0x01 0x0e 0x03 0xe3 0x01 0x0f 0x03 0xe3 0x01 0x12 0x03 0xe3>;
				linux,phandle = <0xe0>;
				phandle = <0xe0>;
			};
		};

		tsadc {

			tsadc-int {
				rockchip,pins = <0x00 0x0f 0x01 0xe3>;
			};

			tsadc-gpio {
				rockchip,pins = <0x00 0x0f 0x00 0xe3>;
				linux,phandle = <0xb9>;
				phandle = <0xb9>;
			};
		};

		hdmi_pin {

			hdmi-cec {
				rockchip,pins = <0x01 0x1f 0x01 0xe3>;
				linux,phandle = <0xd0>;
				phandle = <0xd0>;
			};

			hdmi-hpd {
				rockchip,pins = <0x00 0x11 0x01 0xe8>;
				linux,phandle = <0xd1>;
				phandle = <0xd1>;
			};
		};

		cam_pins {

			cam0-default-pins {
				rockchip,pins = <0x03 0x0d 0x01 0xe3>;
				linux,phandle = <0xaa>;
				phandle = <0xaa>;
			};

			cam0-sleep-pins {
				rockchip,pins = <0x03 0x0d 0x00 0xe3>;
				linux,phandle = <0xab>;
				phandle = <0xab>;
			};
		};

		gpio_detection_pins {

			car-reverse {
				rockchip,pins = <0x00 0x10 0x00 0xe8>;
				linux,phandle = <0xf3>;
				phandle = <0xf3>;
			};
		};

		cif_dvp_pins {

			cif-dvp-d10d11 {
				rockchip,pins = <0x03 0x1d 0x01 0xe3 0x03 0x1e 0x01 0xe3>;
				linux,phandle = <0xa5>;
				phandle = <0xa5>;
			};

			cif-dvp-d2d9 {
				rockchip,pins = <0x02 0x15 0x01 0xe3 0x02 0x16 0x01 0xe3 0x01 0x16 0x01 0xe3 0x01 0x17 0x01 0xe3 0x02 0x10 0x01 0xe3 0x02 0x11 0x01 0xe3 0x03 0x1b 0x01 0xe3 0x03 0x1c 0x01 0xe3>;
				linux,phandle = <0x9d>;
				phandle = <0x9d>;
			};

			cif-dvp-d0d1 {
				rockchip,pins = <0x02 0x13 0x01 0xe3 0x02 0x14 0x01 0xe3>;
				linux,phandle = <0xa4>;
				phandle = <0xa4>;
			};

			cif-dvp-sync {
				rockchip,pins = <0x03 0x18 0x01 0xe3 0x03 0x16 0x01 0xe3>;
				linux,phandle = <0xa6>;
				phandle = <0xa6>;
			};

			cif-dvp-clk-out {
				rockchip,pins = <0x03 0x1a 0x01 0xe3>;
				linux,phandle = <0xa2>;
				phandle = <0xa2>;
			};

			cif-dvp-clk-in {
				rockchip,pins = <0x03 0x17 0x01 0xe3>;
				linux,phandle = <0x9e>;
				phandle = <0x9e>;
			};

			cif-dvp-d2d9-sleep {
				rockchip,pins = <0x02 0x15 0x00 0xe3 0x02 0x16 0x00 0xe3 0x01 0x16 0x00 0xe3 0x01 0x17 0x00 0xe3 0x02 0x10 0x00 0xe3 0x02 0x11 0x00 0xe3 0x03 0x1b 0x00 0xe3 0x03 0x1c 0x00 0xe3>;
				linux,phandle = <0x9f>;
				phandle = <0x9f>;
			};

			cif-dvp-clk-out-sleep {
				rockchip,pins = <0x03 0x1a 0x00 0xe3>;
				linux,phandle = <0xa3>;
				phandle = <0xa3>;
			};

			cif-dvp-clk-in-sleep {
				rockchip,pins = <0x03 0x17 0x00 0xe3>;
				linux,phandle = <0xa0>;
				phandle = <0xa0>;
			};

			cif-dvp-d10d11-sleep {
				rockchip,pins = <0x03 0x1d 0x00 0xe3 0x03 0x1e 0x00 0xe3>;
				linux,phandle = <0xa8>;
				phandle = <0xa8>;
			};

			cif-dvp-d0d1-sleep {
				rockchip,pins = <0x02 0x13 0x00 0xe3 0x02 0x14 0x00 0xe3>;
				linux,phandle = <0xa7>;
				phandle = <0xa7>;
			};

			cif-dvp-sync-sleep {
				rockchip,pins = <0x03 0x18 0x00 0xe3 0x03 0x16 0x00 0xe3>;
				linux,phandle = <0xa9>;
				phandle = <0xa9>;
			};
		};
	};

	screen-init-cmds {
		compatible = "rockchip,screen-init-cmds";
		rockchip,cmd_debug = <0x01>;

		rockchip,init-cmds0 {
			rockchip,init-cmd = <0x11>;
			rockchip,init-cmd-delay = <0x78>;
		};

		rockchip,init-cmds1 {
			rockchip,init-cmd = <0x36>;
			rockchip,init-cmd-value = <0x00>;
			rockchip,init-cmd-delay = <0x00>;
		};

		rockchip,init-cmds2 {
			rockchip,init-cmd = <0x3a>;
			rockchip,init-cmd-value = <0x55>;
			rockchip,init-cmd-delay = <0x00>;
		};

		rockchip,init-cmds3 {
			rockchip,init-cmd = <0xb2>;
			rockchip,init-cmd-value = <0x0c 0x0c 0x00 0x33 0x33>;
			rockchip,init-cmd-delay = <0x00>;
		};

		rockchip,init-cmds4 {
			rockchip,init-cmd = <0xb7>;
			rockchip,init-cmd-value = <0x35>;
			rockchip,init-cmd-delay = <0x00>;
		};

		rockchip,init-cmds5 {
			rockchip,init-cmd = <0xbb>;
			rockchip,init-cmd-value = <0x37>;
			rockchip,init-cmd-delay = <0x00>;
		};

		rockchip,init-cmds6 {
			rockchip,init-cmd = <0xb0>;
			rockchip,init-cmd-value = <0x11 0x04>;
			rockchip,init-cmd-delay = <0x00>;
		};

		rockchip,init-cmds7 {
			rockchip,init-cmd = <0xb1>;
			rockchip,init-cmd-value = <0xc0 0x04 0x0a>;
			rockchip,init-cmd-delay = <0x00>;
		};

		rockchip,init-cmds8 {
			rockchip,init-cmd = <0xbb>;
			rockchip,init-cmd-value = <0x37>;
			rockchip,init-cmd-delay = <0x00>;
		};

		rockchip,init-cmds9 {
			rockchip,init-cmd = <0xc0>;
			rockchip,init-cmd-value = <0x2c>;
			rockchip,init-cmd-delay = <0x00>;
		};

		rockchip,init-cmds10 {
			rockchip,init-cmd = <0xc2>;
			rockchip,init-cmd-value = <0x01>;
			rockchip,init-cmd-delay = <0x00>;
		};

		rockchip,init-cmds11 {
			rockchip,init-cmd = <0xc3>;
			rockchip,init-cmd-value = <0x19>;
			rockchip,init-cmd-delay = <0x00>;
		};

		rockchip,init-cmds12 {
			rockchip,init-cmd = <0xc4>;
			rockchip,init-cmd-value = <0x20>;
			rockchip,init-cmd-delay = <0x00>;
		};

		rockchip,init-cmds13 {
			rockchip,init-cmd = <0xc6>;
			rockchip,init-cmd-value = <0x0f>;
			rockchip,init-cmd-delay = <0x00>;
		};

		rockchip,init-cmds14 {
			rockchip,init-cmd = <0xd0>;
			rockchip,init-cmd-value = <0xa7 0xa1>;
			rockchip,init-cmd-delay = <0x00>;
		};

		rockchip,init-cmds15 {
			rockchip,init-cmd = <0xd0>;
			rockchip,init-cmd-value = <0xa7 0xa1>;
			rockchip,init-cmd-delay = <0x00>;
		};

		rockchip,init-cmds16 {
			rockchip,init-cmd = <0xe0>;
			rockchip,init-cmd-value = <0xd0 0x08 0x0e 0x09 0x09 0x05 0x31 0x33 0x48 0x17 0x14 0x15 0x31 0x34>;
			rockchip,init-cmd-delay = <0x0a>;
		};

		rockchip,init-cmds17 {
			rockchip,init-cmd = <0xe1>;
			rockchip,init-cmd-value = <0xd0 0x08 0x0e 0x09 0x09 0x15 0x31 0x33 0x48 0x17 0x14 0x15 0x31 0x34>;
			rockchip,init-cmd-delay = <0x00>;
		};

		rockchip,init-cmds18 {
			rockchip,init-cmd = <0x2a>;
			rockchip,init-cmd-value = <0x00 0x00 0x00 0xef>;
			rockchip,init-cmd-delay = <0x00>;
		};

		rockchip,init-cmds19 {
			rockchip,init-cmd = <0x2b>;
			rockchip,init-cmd-value = <0x00 0x00 0x01 0x3f>;
			rockchip,init-cmd-delay = <0x00>;
		};

		rockchip,init-cmds20 {
			rockchip,init-cmd = <0x21>;
			rockchip,init-cmd-delay = <0x00>;
		};

		rockchip,init-cmds21 {
			rockchip,init-cmd = <0x29>;
			rockchip,init-cmd-delay = <0x0a>;
		};

		rockchip,init-cmds22 {
			rockchip,init-cmd = <0x2c>;
			rockchip,init-cmd-delay = <0x01>;
		};
	};

	display-timings {
		native-mode = <0xec>;

		timing0 {
			screen-type = <0x01>;
			lvds-format = <0x01>;
			out-face = <0x08>;
			color-mode = <0x00>;
			clock-frequency = <0x11a49a0>;
			screen-width = <0x1e>;
			screen-hight = <0x1e>;
			hactive = <0xf0>;
			vactive = <0xf0>;
			hback-porch = <0x1e>;
			hfront-porch = <0x3c>;
			vback-porch = <0x04>;
			vfront-porch = <0x144>;
			hsync-len = <0x1e>;
			vsync-len = <0x04>;
			hsync-active = <0x00>;
			vsync-active = <0x00>;
			de-active = <0x00>;
			pixelclk-active = <0x00>;
			swap-rb = <0x01>;
			swap-rg = <0x00>;
			swap-gb = <0x00>;
			swap-delta = <0x00>;
			swap-dummy = <0x00>;
			linux,phandle = <0xec>;
			phandle = <0xec>;
		};
	};

	rockchip_suspend {
		rockchip,ctrbits = <0x100166>;
		rockchip,pmic-suspend_gpios = <0x00>;
	};

	ion {
		compatible = "rockchip,ion";
		#address-cells = <0x01>;
		#size-cells = <0x00>;

		dsp {
			compatible = "rockchip,ion-heap";
			rockchip,ion_heap = <0x02>;
			reg = <0x62000000 0x100000>;
		};

		rockchip,ion-heap@4 {
			compatible = "rockchip,ion-heap";
			rockchip,ion_heap = <0x04>;
			reg = <0x00 0x4400000>;
		};

		rockchip,ion-heap@0 {
			compatible = "rockchip,ion-heap";
			rockchip,ion_heap = <0x00>;
		};
	};

	backlight {
		compatible = "pwm-backlight";
		pwms = <0xed 0x00 0xf4240 0x00>;
		brightness-levels = <0x00 0x01 0x02 0x03 0x04 0x05 0x06 0x07 0x08 0x09 0x0a 0x0b 0x0c 0x0d 0x0e 0x0f 0x10 0x11 0x12 0x13 0x14 0x15 0x16 0x17 0x18 0x19 0x1a 0x1b 0x1c 0x1d 0x1e 0x1f 0x20 0x21 0x22 0x23 0x24 0x25 0x26 0x27 0x28 0x29 0x2a 0x2b 0x2c 0x2d 0x2e 0x2f 0x30 0x31 0x32 0x33 0x34 0x35 0x36 0x37 0x38 0x39 0x3a 0x3b 0x3c 0x3d 0x3e 0x3f 0x40 0x41 0x42 0x43 0x44 0x45 0x46 0x47 0x48 0x49 0x4a 0x4b 0x4c 0x4d 0x4e 0x4f 0x50 0x51 0x52 0x53 0x54 0x55 0x56 0x57 0x58 0x59 0x5a 0x5b 0x5c 0x5d 0x5e 0x5f 0x60 0x61 0x62 0x63 0x64 0x65 0x66 0x67 0x68 0x69 0x6a 0x6b 0x6c 0x6d 0x6e 0x6f 0x70 0x71 0x72 0x73 0x74 0x75 0x76 0x77 0x78 0x79 0x7a 0x7b 0x7c 0x7d 0x7e 0x7f 0x80 0x81 0x82 0x83 0x84 0x85 0x86 0x87 0x88 0x89 0x8a 0x8b 0x8c 0x8d 0x8e 0x8f 0x90 0x91 0x92 0x93 0x94 0x95 0x96 0x97 0x98 0x99 0x9a 0x9b 0x9c 0x9d 0x9e 0x9f 0xa0 0xa1 0xa2 0xa3 0xa4 0xa5 0xa6 0xa7 0xa8 0xa9 0xaa 0xab 0xac 0xad 0xae 0xaf 0xb0 0xb1 0xb2 0xb3 0xb4 0xb5 0xb6 0xb7 0xb8 0xb9 0xba 0xbb 0xbc 0xbd 0xbe 0xbf 0xc0 0xc1 0xc2 0xc3 0xc4 0xc5 0xc6 0xc7 0xc8 0xc9 0xca 0xcb 0xcc 0xcd 0xce 0xcf 0xd0 0xd1 0xd2 0xd3 0xd4 0xd5 0xd6 0xd7 0xd8 0xd9 0xda 0xdb 0xdc 0xdd 0xde 0xdf 0xe0 0xe1 0xe2 0xe3 0xe4 0xe5 0xe6 0xe7 0xe8 0xe9 0xea 0xeb 0xec 0xed 0xee 0xef 0xf0 0xf1 0xf2 0xf3 0xf4 0xf5 0xf6 0xf7 0xf8 0xf9 0xfa 0xfb 0xfc 0xfd 0xfe 0xff>;
		default-brightness-level = <0xff>;
	};

	vibrator {
		compatible = "pwm-beeper";
		pwms = <0xee 0x00 0x3e8 0x00>;
		status = "okay";
	};

	io-domains {
		compatible = "rockchip,rv1108-io-voltage-domain";
		rockchip,grf = <0x99>;
		rockchip,pmugrf = <0xe1>;
		status = "okay";
		vccio1-supply = <0xef>;
		vccio2-supply = <0xf0>;
		vccio3-supply = <0xef>;
		vccio5-supply = <0xf0>;
		pmu-supply = <0xef>;
	};

	gpio_poweroff {
		compatible = "gpio-poweroff";
		gpios = <0x9b 0x0d 0x00>;
		status = "okay";
	};

	wireless-wlan {
		compatible = "wlan-platdata";
		wifi_chip_type = "rtl8723cs";
		sdio_vref = <0x00>;
		WIFI,poweren_gpio = <0x9b 0x0b 0x01>;
		WIFI,host_wake_irq = <0x9b 0x03 0x00>;
		status = "okay";
	};

	rockchip_audio {
		compatible = "rockchip,rv1108-audio";

		dais {

			dai0 {
				audio-codec = <0xf1>;
				audio-controller = <0xf2>;
				format = "i2s";
			};
		};
	};

	gpio-det {
		compatible = "gpio-detection";
		status = "disabled";
		pinctrl-0 = <0xf3>;
		pinctrl-names = "default";

		car-reverse {
			gpios = <0x9b 0x10 0x00>;
			linux,debounce-ms = <0x05>;
			label = "car-reverse";
			gpio,wakeup;
		};

		cvbsin_plug {
			gpios = <0xac 0x1f 0x01>;
			linux,debounce-ms = <0x05>;
			label = "cvbsin_plug";
			gpio,wakeup;
		};

		mix_cif0_plug {
			gpios = <0xac 0x19 0x01>;
			linux,debounce-ms = <0x05>;
			label = "mix_cif0_plug";
			gpio,wakeup;
		};

		mix_cif1_plug {
			gpios = <0xac 0x18 0x01>;
			linux,debounce-ms = <0x05>;
			label = "mix_cif1_plug";
			gpio,wakeup;
		};

		mix_cif2_plug {
			gpios = <0xac 0x1b 0x01>;
			linux,debounce-ms = <0x05>;
			label = "mix_cif2_plug";
			gpio,wakeup;
		};

		mix_cif3_plug {
			gpios = <0xac 0x1a 0x01>;
			linux,debounce-ms = <0x05>;
			label = "mix_cif3_plug";
			gpio,wakeup;
		};
	};
};
